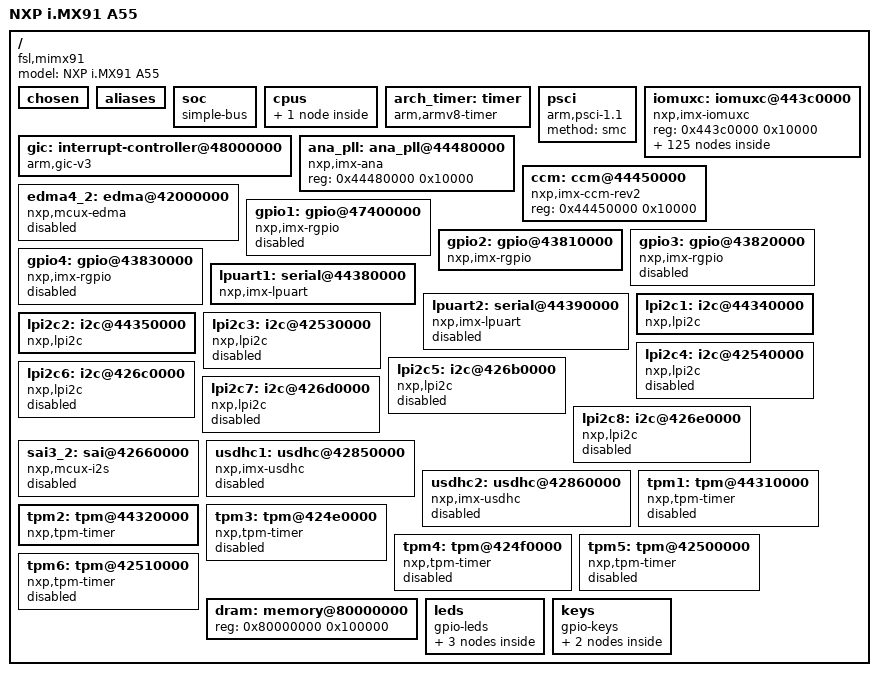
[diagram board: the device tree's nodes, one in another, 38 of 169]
/dts-v1/;

/* node '/' defined in zephyr/dts/common/skeleton.dtsi:9 */
/ {
	#address-cells = < 0x1 >;  /* in zephyr/dts/arm64/nxp/nxp_mimx9131.dtsi:16 */
	#size-cells = < 0x1 >;     /* in zephyr/dts/arm64/nxp/nxp_mimx9131.dtsi:17 */
	model = "NXP i.MX91 A55";  /* in zephyr/boards/nxp/imx91_evk/imx91_evk_mimx9131.dts:14 */
	compatible = "fsl,mimx91"; /* in zephyr/boards/nxp/imx91_evk/imx91_evk_mimx9131.dts:15 */

	/* node '/chosen' defined in zephyr/dts/common/skeleton.dtsi:13 */
	chosen {
		zephyr,console = &lpuart1;    /* in zephyr/boards/nxp/imx91_evk/imx91_evk_mimx9131.dts:18 */
		zephyr,shell-uart = &lpuart1; /* in zephyr/boards/nxp/imx91_evk/imx91_evk_mimx9131.dts:19 */
		zephyr,sram = &dram;          /* in zephyr/boards/nxp/imx91_evk/imx91_evk_mimx9131.dts:21 */
	};

	/* node '/aliases' defined in zephyr/dts/common/skeleton.dtsi:15 */
	aliases {
		led0 = &led_r; /* in zephyr/boards/nxp/imx91_evk/imx91_evk_mimx9131.dts:29 */
		led1 = &led_g; /* in zephyr/boards/nxp/imx91_evk/imx91_evk_mimx9131.dts:30 */
		sw0 = &btn_1;  /* in zephyr/boards/nxp/imx91_evk/imx91_evk_mimx9131.dts:31 */
	};

	/* node '/soc' defined in zephyr/dts/arm64/armv8-a.dtsi:10 */
	soc {
		#address-cells = < 0x1 >;  /* in zephyr/dts/arm64/armv8-a.dtsi:11 */
		#size-cells = < 0x1 >;     /* in zephyr/dts/arm64/armv8-a.dtsi:12 */
		compatible = "simple-bus"; /* in zephyr/dts/arm64/armv8-a.dtsi:13 */
		ranges;                    /* in zephyr/dts/arm64/armv8-a.dtsi:14 */
	};

	/* node '/cpus' defined in zephyr/dts/arm64/nxp/nxp_mimx9131.dtsi:19 */
	cpus {
		#address-cells = < 0x1 >; /* in zephyr/dts/arm64/nxp/nxp_mimx9131.dtsi:20 */
		#size-cells = < 0x0 >;    /* in zephyr/dts/arm64/nxp/nxp_mimx9131.dtsi:21 */

		/* node '/cpus/cpu@0' defined in zephyr/dts/arm64/nxp/nxp_mimx9131.dtsi:23 */
		cpu@0 {
			device_type = "cpu";           /* in zephyr/dts/arm64/nxp/nxp_mimx9131.dtsi:24 */
			compatible = "arm,cortex-a55"; /* in zephyr/dts/arm64/nxp/nxp_mimx9131.dtsi:25 */
			reg = < 0x0 >;                 /* in zephyr/dts/arm64/nxp/nxp_mimx9131.dtsi:26 */
		};
	};

	/* node '/timer' defined in zephyr/dts/arm64/nxp/nxp_mimx9131.dtsi:30 */
	arch_timer: timer {
		compatible = "arm,armv8-timer";    /* in zephyr/dts/arm64/nxp/nxp_mimx9131.dtsi:31 */
		interrupts = < 0x1 0xd 0x2 0xa0 >,
		             < 0x1 0xe 0x2 0xa0 >,
		             < 0x1 0xb 0x2 0xa0 >,
		             < 0x1 0xa 0x2 0xa0 >; /* in zephyr/dts/arm64/nxp/nxp_mimx9131.dtsi:32 */
		interrupt-parent = < &gic >;       /* in zephyr/dts/arm64/nxp/nxp_mimx9131.dtsi:40 */
	};

	/* node '/psci' defined in zephyr/dts/arm64/nxp/nxp_mimx9131.dtsi:43 */
	psci: psci {
		compatible = "arm,psci-1.1"; /* in zephyr/dts/arm64/nxp/nxp_mimx9131.dtsi:44 */
		method = "smc";              /* in zephyr/dts/arm64/nxp/nxp_mimx9131.dtsi:45 */
	};

	/* node '/interrupt-controller@48000000' defined in zephyr/dts/arm64/nxp/nxp_mimx9131.dtsi:48 */
	gic: interrupt-controller@48000000 {
		compatible = "arm,gic-v3",
		             "arm,gic";       /* in zephyr/dts/arm64/nxp/nxp_mimx9131.dtsi:49 */
		reg = < 0x48000000 0x10000 >,
		      < 0x48040000 0xc0000 >; /* in zephyr/dts/arm64/nxp/nxp_mimx9131.dtsi:50 */
		interrupt-controller;         /* in zephyr/dts/arm64/nxp/nxp_mimx9131.dtsi:52 */
		#interrupt-cells = < 0x4 >;   /* in zephyr/dts/arm64/nxp/nxp_mimx9131.dtsi:53 */
		status = "okay";              /* in zephyr/dts/arm64/nxp/nxp_mimx9131.dtsi:54 */
		phandle = < 0x1 >;            /* in zephyr/dts/arm64/nxp/nxp_mimx9131.dtsi:40 */
	};

	/* node '/iomuxc@443c0000' defined in zephyr/dts/arm64/nxp/nxp_mimx9131.dtsi:57 */
	iomuxc: iomuxc@443c0000 {
		compatible = "nxp,imx-iomuxc"; /* in zephyr/dts/arm64/nxp/nxp_mimx9131.dtsi:58 */
		reg = < 0x443c0000 0x10000 >;  /* in zephyr/dts/arm64/nxp/nxp_mimx9131.dtsi:59 */
		status = "okay";               /* in zephyr/dts/arm64/nxp/nxp_mimx9131.dtsi:60 */

		/* node '/iomuxc@443c0000/pinctrl' defined in zephyr/dts/arm64/nxp/nxp_mimx9131.dtsi:62 */
		pinctrl: pinctrl {
			status = "okay";                  /* in zephyr/dts/arm64/nxp/nxp_mimx9131.dtsi:63 */
			compatible = "nxp,imx93-pinctrl"; /* in zephyr/dts/arm64/nxp/nxp_mimx9131.dtsi:64 */

			/* node '/iomuxc@443c0000/pinctrl/uart1_default' defined in zephyr/boards/nxp/imx91_evk/imx91_evk-pinctrl.dtsi:10 */
			uart1_default: uart1_default {
				phandle = < 0x77 >; /* in zephyr/boards/nxp/imx91_evk/imx91_evk_mimx9131.dts:73 */

				/* node '/iomuxc@443c0000/pinctrl/uart1_default/group0' defined in zephyr/boards/nxp/imx91_evk/imx91_evk-pinctrl.dtsi:11 */
				group0 {
					pinmux = < &iomuxc1_uart1_rxd_lpuart_rx_lpuart1_rx >,
					         < &iomuxc1_uart1_txd_lpuart_tx_lpuart1_tx >; /* in zephyr/boards/nxp/imx91_evk/imx91_evk-pinctrl.dtsi:12 */
					bias-pull-up;                                         /* in zephyr/boards/nxp/imx91_evk/imx91_evk-pinctrl.dtsi:14 */
					slew-rate = "slightly_fast";                          /* in zephyr/boards/nxp/imx91_evk/imx91_evk-pinctrl.dtsi:15 */
					drive-strength = "x5";                                /* in zephyr/boards/nxp/imx91_evk/imx91_evk-pinctrl.dtsi:16 */
				};
			};

			/* node '/iomuxc@443c0000/pinctrl/uart2_default' defined in zephyr/boards/nxp/imx91_evk/imx91_evk-pinctrl.dtsi:20 */
			uart2_default: uart2_default {

				/* node '/iomuxc@443c0000/pinctrl/uart2_default/group0' defined in zephyr/boards/nxp/imx91_evk/imx91_evk-pinctrl.dtsi:21 */
				group0 {
					pinmux = < &iomuxc1_uart2_rxd_lpuart_rx_lpuart2_rx >,
					         < &iomuxc1_uart2_txd_lpuart_tx_lpuart2_tx >; /* in zephyr/boards/nxp/imx91_evk/imx91_evk-pinctrl.dtsi:22 */
					bias-pull-up;                                         /* in zephyr/boards/nxp/imx91_evk/imx91_evk-pinctrl.dtsi:24 */
					slew-rate = "slightly_fast";                          /* in zephyr/boards/nxp/imx91_evk/imx91_evk-pinctrl.dtsi:25 */
					drive-strength = "x5";                                /* in zephyr/boards/nxp/imx91_evk/imx91_evk-pinctrl.dtsi:26 */
				};
			};

			/* node '/iomuxc@443c0000/pinctrl/i2c1_default' defined in zephyr/boards/nxp/imx91_evk/imx91_evk-pinctrl.dtsi:30 */
			i2c1_default: i2c1_default {
				phandle = < 0x78 >; /* in zephyr/boards/nxp/imx91_evk/imx91_evk_mimx9131.dts:83 */

				/* node '/iomuxc@443c0000/pinctrl/i2c1_default/group0' defined in zephyr/boards/nxp/imx91_evk/imx91_evk-pinctrl.dtsi:31 */
				group0 {
					pinmux = < &iomuxc1_i2c1_scl_lpi2c_scl_lpi2c1_scl >,
					         < &iomuxc1_i2c1_sda_lpi2c_sda_lpi2c1_sda >; /* in zephyr/boards/nxp/imx91_evk/imx91_evk-pinctrl.dtsi:32 */
					drive-strength = "x5";                               /* in zephyr/boards/nxp/imx91_evk/imx91_evk-pinctrl.dtsi:34 */
					drive-open-drain;                                    /* in zephyr/boards/nxp/imx91_evk/imx91_evk-pinctrl.dtsi:35 */
					slew-rate = "fast";                                  /* in zephyr/boards/nxp/imx91_evk/imx91_evk-pinctrl.dtsi:36 */
					input-enable;                                        /* in zephyr/boards/nxp/imx91_evk/imx91_evk-pinctrl.dtsi:37 */
				};
			};

			/* node '/iomuxc@443c0000/pinctrl/i2c2_default' defined in zephyr/boards/nxp/imx91_evk/imx91_evk-pinctrl.dtsi:41 */
			i2c2_default: i2c2_default {
				phandle = < 0x79 >; /* in zephyr/boards/nxp/imx91_evk/imx91_evk_mimx9131.dts:90 */

				/* node '/iomuxc@443c0000/pinctrl/i2c2_default/group0' defined in zephyr/boards/nxp/imx91_evk/imx91_evk-pinctrl.dtsi:42 */
				group0 {
					pinmux = < &iomuxc1_i2c2_scl_lpi2c_scl_lpi2c2_scl >,
					         < &iomuxc1_i2c2_sda_lpi2c_sda_lpi2c2_sda >; /* in zephyr/boards/nxp/imx91_evk/imx91_evk-pinctrl.dtsi:43 */
					drive-strength = "x5";                               /* in zephyr/boards/nxp/imx91_evk/imx91_evk-pinctrl.dtsi:45 */
					drive-open-drain;                                    /* in zephyr/boards/nxp/imx91_evk/imx91_evk-pinctrl.dtsi:46 */
					slew-rate = "fast";                                  /* in zephyr/boards/nxp/imx91_evk/imx91_evk-pinctrl.dtsi:47 */
					input-enable;                                        /* in zephyr/boards/nxp/imx91_evk/imx91_evk-pinctrl.dtsi:48 */
				};
			};
		};

		/* node '/iomuxc@443c0000/IOMUXC1_CCM_CLKO1_GPIO_IO_GPIO3_IO26' defined in modules/hal/nxp/dts/nxp/nxp_imx/mimx9131cvvxj-pinctrl.dtsi:27 */
		iomuxc1_ccm_clko1_gpio_io_gpio3_io26: IOMUXC1_CCM_CLKO1_GPIO_IO_GPIO3_IO26 {
			pinmux = < 0x443c0088 0x5 0x0 0x0 0x443c0238 >; /* in modules/hal/nxp/dts/nxp/nxp_imx/mimx9131cvvxj-pinctrl.dtsi:28 */
			phandle = < 0x52 >;                             /* in zephyr/dts/arm64/nxp/nxp_mimx9131.dtsi:423 */
		};

		/* node '/iomuxc@443c0000/IOMUXC1_CCM_CLKO2_GPIO_IO_GPIO3_IO27' defined in modules/hal/nxp/dts/nxp/nxp_imx/mimx9131cvvxj-pinctrl.dtsi:36 */
		iomuxc1_ccm_clko2_gpio_io_gpio3_io27: IOMUXC1_CCM_CLKO2_GPIO_IO_GPIO3_IO27 {
			pinmux = < 0x443c008c 0x5 0x0 0x0 0x443c023c >; /* in modules/hal/nxp/dts/nxp/nxp_imx/mimx9131cvvxj-pinctrl.dtsi:37 */
			phandle = < 0x53 >;                             /* in zephyr/dts/arm64/nxp/nxp_mimx9131.dtsi:423 */
		};

		/* node '/iomuxc@443c0000/IOMUXC1_CCM_CLKO3_GPIO_IO_GPIO4_IO28' defined in modules/hal/nxp/dts/nxp/nxp_imx/mimx9131cvvxj-pinctrl.dtsi:45 */
		iomuxc1_ccm_clko3_gpio_io_gpio4_io28: IOMUXC1_CCM_CLKO3_GPIO_IO_GPIO4_IO28 {
			pinmux = < 0x443c0090 0x5 0x0 0x0 0x443c0240 >; /* in modules/hal/nxp/dts/nxp/nxp_imx/mimx9131cvvxj-pinctrl.dtsi:46 */
			phandle = < 0x74 >;                             /* in zephyr/dts/arm64/nxp/nxp_mimx9131.dtsi:458 */
		};

		/* node '/iomuxc@443c0000/IOMUXC1_CCM_CLKO4_GPIO_IO_GPIO4_IO29' defined in modules/hal/nxp/dts/nxp/nxp_imx/mimx9131cvvxj-pinctrl.dtsi:54 */
		iomuxc1_ccm_clko4_gpio_io_gpio4_io29: IOMUXC1_CCM_CLKO4_GPIO_IO_GPIO4_IO29 {
			pinmux = < 0x443c0094 0x5 0x0 0x0 0x443c0244 >; /* in modules/hal/nxp/dts/nxp/nxp_imx/mimx9131cvvxj-pinctrl.dtsi:55 */
			phandle = < 0x75 >;                             /* in zephyr/dts/arm64/nxp/nxp_mimx9131.dtsi:458 */
		};

		/* node '/iomuxc@443c0000/IOMUXC1_DAP_TCLK_SWCLK_GPIO_IO_GPIO3_IO30' defined in modules/hal/nxp/dts/nxp/nxp_imx/mimx9131cvvxj-pinctrl.dtsi:60 */
		iomuxc1_dap_tclk_swclk_gpio_io_gpio3_io30: IOMUXC1_DAP_TCLK_SWCLK_GPIO_IO_GPIO3_IO30 {
			pinmux = < 0x443c0008 0x5 0x0 0x0 0x443c01b8 >; /* in modules/hal/nxp/dts/nxp/nxp_imx/mimx9131cvvxj-pinctrl.dtsi:61 */
			phandle = < 0x56 >;                             /* in zephyr/dts/arm64/nxp/nxp_mimx9131.dtsi:423 */
		};

		/* node '/iomuxc@443c0000/IOMUXC1_DAP_TDI_GPIO_IO_GPIO3_IO28' defined in modules/hal/nxp/dts/nxp/nxp_imx/mimx9131cvvxj-pinctrl.dtsi:75 */
		iomuxc1_dap_tdi_gpio_io_gpio3_io28: IOMUXC1_DAP_TDI_GPIO_IO_GPIO3_IO28 {
			pinmux = < 0x443c0000 0x5 0x0 0x0 0x443c01b0 >; /* in modules/hal/nxp/dts/nxp/nxp_imx/mimx9131cvvxj-pinctrl.dtsi:76 */
			phandle = < 0x54 >;                             /* in zephyr/dts/arm64/nxp/nxp_mimx9131.dtsi:423 */
		};

		/* node '/iomuxc@443c0000/IOMUXC1_DAP_TDO_TRACESWO_GPIO_IO_GPIO3_IO31' defined in modules/hal/nxp/dts/nxp/nxp_imx/mimx9131cvvxj-pinctrl.dtsi:93 */
		iomuxc1_dap_tdo_traceswo_gpio_io_gpio3_io31: IOMUXC1_DAP_TDO_TRACESWO_GPIO_IO_GPIO3_IO31 {
			pinmux = < 0x443c000c 0x5 0x0 0x0 0x443c01bc >; /* in modules/hal/nxp/dts/nxp/nxp_imx/mimx9131cvvxj-pinctrl.dtsi:94 */
			phandle = < 0x57 >;                             /* in zephyr/dts/arm64/nxp/nxp_mimx9131.dtsi:423 */
		};

		/* node '/iomuxc@443c0000/IOMUXC1_DAP_TMS_SWDIO_GPIO_IO_GPIO3_IO29' defined in modules/hal/nxp/dts/nxp/nxp_imx/mimx9131cvvxj-pinctrl.dtsi:108 */
		iomuxc1_dap_tms_swdio_gpio_io_gpio3_io29: IOMUXC1_DAP_TMS_SWDIO_GPIO_IO_GPIO3_IO29 {
			pinmux = < 0x443c0004 0x5 0x0 0x0 0x443c01b4 >; /* in modules/hal/nxp/dts/nxp/nxp_imx/mimx9131cvvxj-pinctrl.dtsi:109 */
			phandle = < 0x55 >;                             /* in zephyr/dts/arm64/nxp/nxp_mimx9131.dtsi:423 */
		};

		/* node '/iomuxc@443c0000/IOMUXC1_ENET1_MDC_GPIO_IO_GPIO4_IO0' defined in modules/hal/nxp/dts/nxp/nxp_imx/mimx9131cvvxj-pinctrl.dtsi:123 */
		iomuxc1_enet1_mdc_gpio_io_gpio4_io0: IOMUXC1_ENET1_MDC_GPIO_IO_GPIO4_IO0 {
			pinmux = < 0x443c0098 0x5 0x0 0x0 0x443c0248 >; /* in modules/hal/nxp/dts/nxp/nxp_imx/mimx9131cvvxj-pinctrl.dtsi:124 */
			phandle = < 0x58 >;                             /* in zephyr/dts/arm64/nxp/nxp_mimx9131.dtsi:458 */
		};

		/* node '/iomuxc@443c0000/IOMUXC1_ENET1_MDIO_GPIO_IO_GPIO4_IO1' defined in modules/hal/nxp/dts/nxp/nxp_imx/mimx9131cvvxj-pinctrl.dtsi:144 */
		iomuxc1_enet1_mdio_gpio_io_gpio4_io1: IOMUXC1_ENET1_MDIO_GPIO_IO_GPIO4_IO1 {
			pinmux = < 0x443c009c 0x5 0x0 0x0 0x443c024c >; /* in modules/hal/nxp/dts/nxp/nxp_imx/mimx9131cvvxj-pinctrl.dtsi:145 */
			phandle = < 0x59 >;                             /* in zephyr/dts/arm64/nxp/nxp_mimx9131.dtsi:458 */
		};

		/* node '/iomuxc@443c0000/IOMUXC1_ENET1_RD0_GPIO_IO_GPIO4_IO10' defined in modules/hal/nxp/dts/nxp/nxp_imx/mimx9131cvvxj-pinctrl.dtsi:165 */
		iomuxc1_enet1_rd0_gpio_io_gpio4_io10: IOMUXC1_ENET1_RD0_GPIO_IO_GPIO4_IO10 {
			pinmux = < 0x443c00c0 0x5 0x0 0x0 0x443c0270 >; /* in modules/hal/nxp/dts/nxp/nxp_imx/mimx9131cvvxj-pinctrl.dtsi:166 */
			phandle = < 0x62 >;                             /* in zephyr/dts/arm64/nxp/nxp_mimx9131.dtsi:458 */
		};

		/* node '/iomuxc@443c0000/IOMUXC1_ENET1_RD1_GPIO_IO_GPIO4_IO11' defined in modules/hal/nxp/dts/nxp/nxp_imx/mimx9131cvvxj-pinctrl.dtsi:177 */
		iomuxc1_enet1_rd1_gpio_io_gpio4_io11: IOMUXC1_ENET1_RD1_GPIO_IO_GPIO4_IO11 {
			pinmux = < 0x443c00c4 0x5 0x0 0x0 0x443c0274 >; /* in modules/hal/nxp/dts/nxp/nxp_imx/mimx9131cvvxj-pinctrl.dtsi:178 */
			phandle = < 0x63 >;                             /* in zephyr/dts/arm64/nxp/nxp_mimx9131.dtsi:458 */
		};

		/* node '/iomuxc@443c0000/IOMUXC1_ENET1_RD2_GPIO_IO_GPIO4_IO12' defined in modules/hal/nxp/dts/nxp/nxp_imx/mimx9131cvvxj-pinctrl.dtsi:192 */
		iomuxc1_enet1_rd2_gpio_io_gpio4_io12: IOMUXC1_ENET1_RD2_GPIO_IO_GPIO4_IO12 {
			pinmux = < 0x443c00c8 0x5 0x0 0x0 0x443c0278 >; /* in modules/hal/nxp/dts/nxp/nxp_imx/mimx9131cvvxj-pinctrl.dtsi:193 */
			phandle = < 0x64 >;                             /* in zephyr/dts/arm64/nxp/nxp_mimx9131.dtsi:458 */
		};

		/* node '/iomuxc@443c0000/IOMUXC1_ENET1_RD3_GPIO_IO_GPIO4_IO13' defined in modules/hal/nxp/dts/nxp/nxp_imx/mimx9131cvvxj-pinctrl.dtsi:204 */
		iomuxc1_enet1_rd3_gpio_io_gpio4_io13: IOMUXC1_ENET1_RD3_GPIO_IO_GPIO4_IO13 {
			pinmux = < 0x443c00cc 0x5 0x0 0x0 0x443c027c >; /* in modules/hal/nxp/dts/nxp/nxp_imx/mimx9131cvvxj-pinctrl.dtsi:205 */
			phandle = < 0x65 >;                             /* in zephyr/dts/arm64/nxp/nxp_mimx9131.dtsi:458 */
		};

		/* node '/iomuxc@443c0000/IOMUXC1_ENET1_RXC_GPIO_IO_GPIO4_IO9' defined in modules/hal/nxp/dts/nxp/nxp_imx/mimx9131cvvxj-pinctrl.dtsi:219 */
		iomuxc1_enet1_rxc_gpio_io_gpio4_io9: IOMUXC1_ENET1_RXC_GPIO_IO_GPIO4_IO9 {
			pinmux = < 0x443c00bc 0x5 0x0 0x0 0x443c026c >; /* in modules/hal/nxp/dts/nxp/nxp_imx/mimx9131cvvxj-pinctrl.dtsi:220 */
			phandle = < 0x61 >;                             /* in zephyr/dts/arm64/nxp/nxp_mimx9131.dtsi:458 */
		};

		/* node '/iomuxc@443c0000/IOMUXC1_ENET1_RX_CTL_GPIO_IO_GPIO4_IO8' defined in modules/hal/nxp/dts/nxp/nxp_imx/mimx9131cvvxj-pinctrl.dtsi:231 */
		iomuxc1_enet1_rx_ctl_gpio_io_gpio4_io8: IOMUXC1_ENET1_RX_CTL_GPIO_IO_GPIO4_IO8 {
			pinmux = < 0x443c00b8 0x5 0x0 0x0 0x443c0268 >; /* in modules/hal/nxp/dts/nxp/nxp_imx/mimx9131cvvxj-pinctrl.dtsi:232 */
			phandle = < 0x60 >;                             /* in zephyr/dts/arm64/nxp/nxp_mimx9131.dtsi:458 */
		};

		/* node '/iomuxc@443c0000/IOMUXC1_ENET1_TD0_GPIO_IO_GPIO4_IO5' defined in modules/hal/nxp/dts/nxp/nxp_imx/mimx9131cvvxj-pinctrl.dtsi:249 */
		iomuxc1_enet1_td0_gpio_io_gpio4_io5: IOMUXC1_ENET1_TD0_GPIO_IO_GPIO4_IO5 {
			pinmux = < 0x443c00ac 0x5 0x0 0x0 0x443c025c >; /* in modules/hal/nxp/dts/nxp/nxp_imx/mimx9131cvvxj-pinctrl.dtsi:250 */
			phandle = < 0x5d >;                             /* in zephyr/dts/arm64/nxp/nxp_mimx9131.dtsi:458 */
		};

		/* node '/iomuxc@443c0000/IOMUXC1_ENET1_TD1_GPIO_IO_GPIO4_IO4' defined in modules/hal/nxp/dts/nxp/nxp_imx/mimx9131cvvxj-pinctrl.dtsi:261 */
		iomuxc1_enet1_td1_gpio_io_gpio4_io4: IOMUXC1_ENET1_TD1_GPIO_IO_GPIO4_IO4 {
			pinmux = < 0x443c00a8 0x5 0x0 0x0 0x443c0258 >; /* in modules/hal/nxp/dts/nxp/nxp_imx/mimx9131cvvxj-pinctrl.dtsi:262 */
			phandle = < 0x5c >;                             /* in zephyr/dts/arm64/nxp/nxp_mimx9131.dtsi:458 */
		};

		/* node '/iomuxc@443c0000/IOMUXC1_ENET1_TD2_GPIO_IO_GPIO4_IO3' defined in modules/hal/nxp/dts/nxp/nxp_imx/mimx9131cvvxj-pinctrl.dtsi:288 */
		iomuxc1_enet1_td2_gpio_io_gpio4_io3: IOMUXC1_ENET1_TD2_GPIO_IO_GPIO4_IO3 {
			pinmux = < 0x443c00a4 0x5 0x0 0x0 0x443c0254 >; /* in modules/hal/nxp/dts/nxp/nxp_imx/mimx9131cvvxj-pinctrl.dtsi:289 */
			phandle = < 0x5b >;                             /* in zephyr/dts/arm64/nxp/nxp_mimx9131.dtsi:458 */
		};

		/* node '/iomuxc@443c0000/IOMUXC1_ENET1_TD3_GPIO_IO_GPIO4_IO2' defined in modules/hal/nxp/dts/nxp/nxp_imx/mimx9131cvvxj-pinctrl.dtsi:306 */
		iomuxc1_enet1_td3_gpio_io_gpio4_io2: IOMUXC1_ENET1_TD3_GPIO_IO_GPIO4_IO2 {
			pinmux = < 0x443c00a0 0x5 0x0 0x0 0x443c0250 >; /* in modules/hal/nxp/dts/nxp/nxp_imx/mimx9131cvvxj-pinctrl.dtsi:307 */
			phandle = < 0x5a >;                             /* in zephyr/dts/arm64/nxp/nxp_mimx9131.dtsi:458 */
		};

		/* node '/iomuxc@443c0000/IOMUXC1_ENET1_TXC_GPIO_IO_GPIO4_IO7' defined in modules/hal/nxp/dts/nxp/nxp_imx/mimx9131cvvxj-pinctrl.dtsi:324 */
		iomuxc1_enet1_txc_gpio_io_gpio4_io7: IOMUXC1_ENET1_TXC_GPIO_IO_GPIO4_IO7 {
			pinmux = < 0x443c00b4 0x5 0x0 0x0 0x443c0264 >; /* in modules/hal/nxp/dts/nxp/nxp_imx/mimx9131cvvxj-pinctrl.dtsi:325 */
			phandle = < 0x5f >;                             /* in zephyr/dts/arm64/nxp/nxp_mimx9131.dtsi:458 */
		};

		/* node '/iomuxc@443c0000/IOMUXC1_ENET1_TX_CTL_GPIO_IO_GPIO4_IO6' defined in modules/hal/nxp/dts/nxp/nxp_imx/mimx9131cvvxj-pinctrl.dtsi:336 */
		iomuxc1_enet1_tx_ctl_gpio_io_gpio4_io6: IOMUXC1_ENET1_TX_CTL_GPIO_IO_GPIO4_IO6 {
			pinmux = < 0x443c00b0 0x5 0x0 0x0 0x443c0260 >; /* in modules/hal/nxp/dts/nxp/nxp_imx/mimx9131cvvxj-pinctrl.dtsi:337 */
			phandle = < 0x5e >;                             /* in zephyr/dts/arm64/nxp/nxp_mimx9131.dtsi:458 */
		};

		/* node '/iomuxc@443c0000/IOMUXC1_ENET2_MDC_GPIO_IO_GPIO4_IO14' defined in modules/hal/nxp/dts/nxp/nxp_imx/mimx9131cvvxj-pinctrl.dtsi:351 */
		iomuxc1_enet2_mdc_gpio_io_gpio4_io14: IOMUXC1_ENET2_MDC_GPIO_IO_GPIO4_IO14 {
			pinmux = < 0x443c00d0 0x5 0x0 0x0 0x443c0280 >; /* in modules/hal/nxp/dts/nxp/nxp_imx/mimx9131cvvxj-pinctrl.dtsi:352 */
			phandle = < 0x66 >;                             /* in zephyr/dts/arm64/nxp/nxp_mimx9131.dtsi:458 */
		};

		/* node '/iomuxc@443c0000/IOMUXC1_ENET2_MDIO_GPIO_IO_GPIO4_IO15' defined in modules/hal/nxp/dts/nxp/nxp_imx/mimx9131cvvxj-pinctrl.dtsi:369 */
		iomuxc1_enet2_mdio_gpio_io_gpio4_io15: IOMUXC1_ENET2_MDIO_GPIO_IO_GPIO4_IO15 {
			pinmux = < 0x443c00d4 0x5 0x0 0x0 0x443c0284 >; /* in modules/hal/nxp/dts/nxp/nxp_imx/mimx9131cvvxj-pinctrl.dtsi:370 */
			phandle = < 0x67 >;                             /* in zephyr/dts/arm64/nxp/nxp_mimx9131.dtsi:458 */
		};

		/* node '/iomuxc@443c0000/IOMUXC1_ENET2_RD0_GPIO_IO_GPIO4_IO24' defined in modules/hal/nxp/dts/nxp/nxp_imx/mimx9131cvvxj-pinctrl.dtsi:387 */
		iomuxc1_enet2_rd0_gpio_io_gpio4_io24: IOMUXC1_ENET2_RD0_GPIO_IO_GPIO4_IO24 {
			pinmux = < 0x443c00f8 0x5 0x0 0x0 0x443c02a8 >; /* in modules/hal/nxp/dts/nxp/nxp_imx/mimx9131cvvxj-pinctrl.dtsi:388 */
			phandle = < 0x70 >;                             /* in zephyr/dts/arm64/nxp/nxp_mimx9131.dtsi:458 */
		};

		/* node '/iomuxc@443c0000/IOMUXC1_ENET2_RD1_GPIO_IO_GPIO4_IO25' defined in modules/hal/nxp/dts/nxp/nxp_imx/mimx9131cvvxj-pinctrl.dtsi:402 */
		iomuxc1_enet2_rd1_gpio_io_gpio4_io25: IOMUXC1_ENET2_RD1_GPIO_IO_GPIO4_IO25 {
			pinmux = < 0x443c00fc 0x5 0x0 0x0 0x443c02ac >; /* in modules/hal/nxp/dts/nxp/nxp_imx/mimx9131cvvxj-pinctrl.dtsi:403 */
			phandle = < 0x71 >;                             /* in zephyr/dts/arm64/nxp/nxp_mimx9131.dtsi:458 */
		};

		/* node '/iomuxc@443c0000/IOMUXC1_ENET2_RD2_GPIO_IO_GPIO4_IO26' defined in modules/hal/nxp/dts/nxp/nxp_imx/mimx9131cvvxj-pinctrl.dtsi:417 */
		iomuxc1_enet2_rd2_gpio_io_gpio4_io26: IOMUXC1_ENET2_RD2_GPIO_IO_GPIO4_IO26 {
			pinmux = < 0x443c0100 0x5 0x0 0x0 0x443c02b0 >; /* in modules/hal/nxp/dts/nxp/nxp_imx/mimx9131cvvxj-pinctrl.dtsi:418 */
			phandle = < 0x72 >;                             /* in zephyr/dts/arm64/nxp/nxp_mimx9131.dtsi:458 */
		};

		/* node '/iomuxc@443c0000/IOMUXC1_ENET2_RD3_GPIO_IO_GPIO4_IO27' defined in modules/hal/nxp/dts/nxp/nxp_imx/mimx9131cvvxj-pinctrl.dtsi:438 */
		iomuxc1_enet2_rd3_gpio_io_gpio4_io27: IOMUXC1_ENET2_RD3_GPIO_IO_GPIO4_IO27 {
			pinmux = < 0x443c0104 0x5 0x0 0x0 0x443c02b4 >; /* in modules/hal/nxp/dts/nxp/nxp_imx/mimx9131cvvxj-pinctrl.dtsi:439 */
			phandle = < 0x73 >;                             /* in zephyr/dts/arm64/nxp/nxp_mimx9131.dtsi:458 */
		};

		/* node '/iomuxc@443c0000/IOMUXC1_ENET2_RXC_GPIO_IO_GPIO4_IO23' defined in modules/hal/nxp/dts/nxp/nxp_imx/mimx9131cvvxj-pinctrl.dtsi:459 */
		iomuxc1_enet2_rxc_gpio_io_gpio4_io23: IOMUXC1_ENET2_RXC_GPIO_IO_GPIO4_IO23 {
			pinmux = < 0x443c00f4 0x5 0x0 0x0 0x443c02a4 >; /* in modules/hal/nxp/dts/nxp/nxp_imx/mimx9131cvvxj-pinctrl.dtsi:460 */
			phandle = < 0x6f >;                             /* in zephyr/dts/arm64/nxp/nxp_mimx9131.dtsi:458 */
		};

		/* node '/iomuxc@443c0000/IOMUXC1_ENET2_RX_CTL_GPIO_IO_GPIO4_IO22' defined in modules/hal/nxp/dts/nxp/nxp_imx/mimx9131cvvxj-pinctrl.dtsi:471 */
		iomuxc1_enet2_rx_ctl_gpio_io_gpio4_io22: IOMUXC1_ENET2_RX_CTL_GPIO_IO_GPIO4_IO22 {
			pinmux = < 0x443c00f0 0x5 0x0 0x0 0x443c02a0 >; /* in modules/hal/nxp/dts/nxp/nxp_imx/mimx9131cvvxj-pinctrl.dtsi:472 */
			phandle = < 0x6e >;                             /* in zephyr/dts/arm64/nxp/nxp_mimx9131.dtsi:458 */
		};

		/* node '/iomuxc@443c0000/IOMUXC1_ENET2_TD0_GPIO_IO_GPIO4_IO19' defined in modules/hal/nxp/dts/nxp/nxp_imx/mimx9131cvvxj-pinctrl.dtsi:489 */
		iomuxc1_enet2_td0_gpio_io_gpio4_io19: IOMUXC1_ENET2_TD0_GPIO_IO_GPIO4_IO19 {
			pinmux = < 0x443c00e4 0x5 0x0 0x0 0x443c0294 >; /* in modules/hal/nxp/dts/nxp/nxp_imx/mimx9131cvvxj-pinctrl.dtsi:490 */
			phandle = < 0x6b >;                             /* in zephyr/dts/arm64/nxp/nxp_mimx9131.dtsi:458 */
		};

		/* node '/iomuxc@443c0000/IOMUXC1_ENET2_TD1_GPIO_IO_GPIO4_IO18' defined in modules/hal/nxp/dts/nxp/nxp_imx/mimx9131cvvxj-pinctrl.dtsi:504 */
		iomuxc1_enet2_td1_gpio_io_gpio4_io18: IOMUXC1_ENET2_TD1_GPIO_IO_GPIO4_IO18 {
			pinmux = < 0x443c00e0 0x5 0x0 0x0 0x443c0290 >; /* in modules/hal/nxp/dts/nxp/nxp_imx/mimx9131cvvxj-pinctrl.dtsi:505 */
			phandle = < 0x6a >;                             /* in zephyr/dts/arm64/nxp/nxp_mimx9131.dtsi:458 */
		};

		/* node '/iomuxc@443c0000/IOMUXC1_ENET2_TD2_GPIO_IO_GPIO4_IO17' defined in modules/hal/nxp/dts/nxp/nxp_imx/mimx9131cvvxj-pinctrl.dtsi:522 */
		iomuxc1_enet2_td2_gpio_io_gpio4_io17: IOMUXC1_ENET2_TD2_GPIO_IO_GPIO4_IO17 {
			pinmux = < 0x443c00dc 0x5 0x0 0x0 0x443c028c >; /* in modules/hal/nxp/dts/nxp/nxp_imx/mimx9131cvvxj-pinctrl.dtsi:523 */
			phandle = < 0x69 >;                             /* in zephyr/dts/arm64/nxp/nxp_mimx9131.dtsi:458 */
		};

		/* node '/iomuxc@443c0000/IOMUXC1_ENET2_TD3_GPIO_IO_GPIO4_IO16' defined in modules/hal/nxp/dts/nxp/nxp_imx/mimx9131cvvxj-pinctrl.dtsi:534 */
		iomuxc1_enet2_td3_gpio_io_gpio4_io16: IOMUXC1_ENET2_TD3_GPIO_IO_GPIO4_IO16 {
			pinmux = < 0x443c00d8 0x5 0x0 0x0 0x443c0288 >; /* in modules/hal/nxp/dts/nxp/nxp_imx/mimx9131cvvxj-pinctrl.dtsi:535 */
			phandle = < 0x68 >;                             /* in zephyr/dts/arm64/nxp/nxp_mimx9131.dtsi:458 */
		};

		/* node '/iomuxc@443c0000/IOMUXC1_ENET2_TXC_GPIO_IO_GPIO4_IO21' defined in modules/hal/nxp/dts/nxp/nxp_imx/mimx9131cvvxj-pinctrl.dtsi:552 */
		iomuxc1_enet2_txc_gpio_io_gpio4_io21: IOMUXC1_ENET2_TXC_GPIO_IO_GPIO4_IO21 {
			pinmux = < 0x443c00ec 0x5 0x0 0x0 0x443c029c >; /* in modules/hal/nxp/dts/nxp/nxp_imx/mimx9131cvvxj-pinctrl.dtsi:553 */
			phandle = < 0x6d >;                             /* in zephyr/dts/arm64/nxp/nxp_mimx9131.dtsi:458 */
		};

		/* node '/iomuxc@443c0000/IOMUXC1_ENET2_TX_CTL_GPIO_IO_GPIO4_IO20' defined in modules/hal/nxp/dts/nxp/nxp_imx/mimx9131cvvxj-pinctrl.dtsi:567 */
		iomuxc1_enet2_tx_ctl_gpio_io_gpio4_io20: IOMUXC1_ENET2_TX_CTL_GPIO_IO_GPIO4_IO20 {
			pinmux = < 0x443c00e8 0x5 0x0 0x0 0x443c0298 >; /* in modules/hal/nxp/dts/nxp/nxp_imx/mimx9131cvvxj-pinctrl.dtsi:568 */
			phandle = < 0x6c >;                             /* in zephyr/dts/arm64/nxp/nxp_mimx9131.dtsi:458 */
		};

		/* node '/iomuxc@443c0000/IOMUXC1_GPIO_IO00_GPIO_IO_GPIO2_IO0' defined in modules/hal/nxp/dts/nxp/nxp_imx/mimx9131cvvxj-pinctrl.dtsi:582 */
		iomuxc1_gpio_io00_gpio_io_gpio2_io0: IOMUXC1_GPIO_IO00_GPIO_IO_GPIO2_IO0 {
			pinmux = < 0x443c0010 0x0 0x0 0x0 0x443c01c0 >; /* in modules/hal/nxp/dts/nxp/nxp_imx/mimx9131cvvxj-pinctrl.dtsi:583 */
			phandle = < 0x1a >;                             /* in zephyr/dts/arm64/nxp/nxp_mimx9131.dtsi:390 */
		};

		/* node '/iomuxc@443c0000/IOMUXC1_GPIO_IO01_GPIO_IO_GPIO2_IO1' defined in modules/hal/nxp/dts/nxp/nxp_imx/mimx9131cvvxj-pinctrl.dtsi:606 */
		iomuxc1_gpio_io01_gpio_io_gpio2_io1: IOMUXC1_GPIO_IO01_GPIO_IO_GPIO2_IO1 {
			pinmux = < 0x443c0014 0x0 0x0 0x0 0x443c01c4 >; /* in modules/hal/nxp/dts/nxp/nxp_imx/mimx9131cvvxj-pinctrl.dtsi:607 */
			phandle = < 0x1b >;                             /* in zephyr/dts/arm64/nxp/nxp_mimx9131.dtsi:390 */
		};

		/* node '/iomuxc@443c0000/IOMUXC1_GPIO_IO02_GPIO_IO_GPIO2_IO2' defined in modules/hal/nxp/dts/nxp/nxp_imx/mimx9131cvvxj-pinctrl.dtsi:630 */
		iomuxc1_gpio_io02_gpio_io_gpio2_io2: IOMUXC1_GPIO_IO02_GPIO_IO_GPIO2_IO2 {
			pinmux = < 0x443c0018 0x0 0x0 0x0 0x443c01c8 >; /* in modules/hal/nxp/dts/nxp/nxp_imx/mimx9131cvvxj-pinctrl.dtsi:631 */
			phandle = < 0x1c >;                             /* in zephyr/dts/arm64/nxp/nxp_mimx9131.dtsi:390 */
		};

		/* node '/iomuxc@443c0000/IOMUXC1_GPIO_IO03_GPIO_IO_GPIO2_IO3' defined in modules/hal/nxp/dts/nxp/nxp_imx/mimx9131cvvxj-pinctrl.dtsi:654 */
		iomuxc1_gpio_io03_gpio_io_gpio2_io3: IOMUXC1_GPIO_IO03_GPIO_IO_GPIO2_IO3 {
			pinmux = < 0x443c001c 0x0 0x0 0x0 0x443c01cc >; /* in modules/hal/nxp/dts/nxp/nxp_imx/mimx9131cvvxj-pinctrl.dtsi:655 */
			phandle = < 0x1d >;                             /* in zephyr/dts/arm64/nxp/nxp_mimx9131.dtsi:390 */
		};

		/* node '/iomuxc@443c0000/IOMUXC1_GPIO_IO04_GPIO_IO_GPIO2_IO4' defined in modules/hal/nxp/dts/nxp/nxp_imx/mimx9131cvvxj-pinctrl.dtsi:678 */
		iomuxc1_gpio_io04_gpio_io_gpio2_io4: IOMUXC1_GPIO_IO04_GPIO_IO_GPIO2_IO4 {
			pinmux = < 0x443c0020 0x0 0x0 0x0 0x443c01d0 >; /* in modules/hal/nxp/dts/nxp/nxp_imx/mimx9131cvvxj-pinctrl.dtsi:679 */
			phandle = < 0x1e >;                             /* in zephyr/dts/arm64/nxp/nxp_mimx9131.dtsi:390 */
		};

		/* node '/iomuxc@443c0000/IOMUXC1_GPIO_IO05_GPIO_IO_GPIO2_IO5' defined in modules/hal/nxp/dts/nxp/nxp_imx/mimx9131cvvxj-pinctrl.dtsi:702 */
		iomuxc1_gpio_io05_gpio_io_gpio2_io5: IOMUXC1_GPIO_IO05_GPIO_IO_GPIO2_IO5 {
			pinmux = < 0x443c0024 0x0 0x0 0x0 0x443c01d4 >; /* in modules/hal/nxp/dts/nxp/nxp_imx/mimx9131cvvxj-pinctrl.dtsi:703 */
			phandle = < 0x1f >;                             /* in zephyr/dts/arm64/nxp/nxp_mimx9131.dtsi:390 */
		};

		/* node '/iomuxc@443c0000/IOMUXC1_GPIO_IO06_GPIO_IO_GPIO2_IO6' defined in modules/hal/nxp/dts/nxp/nxp_imx/mimx9131cvvxj-pinctrl.dtsi:726 */
		iomuxc1_gpio_io06_gpio_io_gpio2_io6: IOMUXC1_GPIO_IO06_GPIO_IO_GPIO2_IO6 {
			pinmux = < 0x443c0028 0x0 0x0 0x0 0x443c01d8 >; /* in modules/hal/nxp/dts/nxp/nxp_imx/mimx9131cvvxj-pinctrl.dtsi:727 */
			phandle = < 0x20 >;                             /* in zephyr/dts/arm64/nxp/nxp_mimx9131.dtsi:390 */
		};

		/* node '/iomuxc@443c0000/IOMUXC1_GPIO_IO07_GPIO_IO_GPIO2_IO7' defined in modules/hal/nxp/dts/nxp/nxp_imx/mimx9131cvvxj-pinctrl.dtsi:750 */
		iomuxc1_gpio_io07_gpio_io_gpio2_io7: IOMUXC1_GPIO_IO07_GPIO_IO_GPIO2_IO7 {
			pinmux = < 0x443c002c 0x0 0x0 0x0 0x443c01dc >; /* in modules/hal/nxp/dts/nxp/nxp_imx/mimx9131cvvxj-pinctrl.dtsi:751 */
			phandle = < 0x21 >;                             /* in zephyr/dts/arm64/nxp/nxp_mimx9131.dtsi:390 */
		};

		/* node '/iomuxc@443c0000/IOMUXC1_GPIO_IO08_GPIO_IO_GPIO2_IO8' defined in modules/hal/nxp/dts/nxp/nxp_imx/mimx9131cvvxj-pinctrl.dtsi:774 */
		iomuxc1_gpio_io08_gpio_io_gpio2_io8: IOMUXC1_GPIO_IO08_GPIO_IO_GPIO2_IO8 {
			pinmux = < 0x443c0030 0x0 0x0 0x0 0x443c01e0 >; /* in modules/hal/nxp/dts/nxp/nxp_imx/mimx9131cvvxj-pinctrl.dtsi:775 */
			phandle = < 0x22 >;                             /* in zephyr/dts/arm64/nxp/nxp_mimx9131.dtsi:390 */
		};

		/* node '/iomuxc@443c0000/IOMUXC1_GPIO_IO09_GPIO_IO_GPIO2_IO9' defined in modules/hal/nxp/dts/nxp/nxp_imx/mimx9131cvvxj-pinctrl.dtsi:798 */
		iomuxc1_gpio_io09_gpio_io_gpio2_io9: IOMUXC1_GPIO_IO09_GPIO_IO_GPIO2_IO9 {
			pinmux = < 0x443c0034 0x0 0x0 0x0 0x443c01e4 >; /* in modules/hal/nxp/dts/nxp/nxp_imx/mimx9131cvvxj-pinctrl.dtsi:799 */
			phandle = < 0x23 >;                             /* in zephyr/dts/arm64/nxp/nxp_mimx9131.dtsi:390 */
		};

		/* node '/iomuxc@443c0000/IOMUXC1_GPIO_IO10_GPIO_IO_GPIO2_IO10' defined in modules/hal/nxp/dts/nxp/nxp_imx/mimx9131cvvxj-pinctrl.dtsi:822 */
		iomuxc1_gpio_io10_gpio_io_gpio2_io10: IOMUXC1_GPIO_IO10_GPIO_IO_GPIO2_IO10 {
			pinmux = < 0x443c0038 0x0 0x0 0x0 0x443c01e8 >; /* in modules/hal/nxp/dts/nxp/nxp_imx/mimx9131cvvxj-pinctrl.dtsi:823 */
			phandle = < 0x24 >;                             /* in zephyr/dts/arm64/nxp/nxp_mimx9131.dtsi:390 */
		};

		/* node '/iomuxc@443c0000/IOMUXC1_GPIO_IO11_GPIO_IO_GPIO2_IO11' defined in modules/hal/nxp/dts/nxp/nxp_imx/mimx9131cvvxj-pinctrl.dtsi:846 */
		iomuxc1_gpio_io11_gpio_io_gpio2_io11: IOMUXC1_GPIO_IO11_GPIO_IO_GPIO2_IO11 {
			pinmux = < 0x443c003c 0x0 0x0 0x0 0x443c01ec >; /* in modules/hal/nxp/dts/nxp/nxp_imx/mimx9131cvvxj-pinctrl.dtsi:847 */
			phandle = < 0x25 >;                             /* in zephyr/dts/arm64/nxp/nxp_mimx9131.dtsi:390 */
		};

		/* node '/iomuxc@443c0000/IOMUXC1_GPIO_IO12_GPIO_IO_GPIO2_IO12' defined in modules/hal/nxp/dts/nxp/nxp_imx/mimx9131cvvxj-pinctrl.dtsi:867 */
		iomuxc1_gpio_io12_gpio_io_gpio2_io12: IOMUXC1_GPIO_IO12_GPIO_IO_GPIO2_IO12 {
			pinmux = < 0x443c0040 0x0 0x0 0x0 0x443c01f0 >; /* in modules/hal/nxp/dts/nxp/nxp_imx/mimx9131cvvxj-pinctrl.dtsi:868 */
			phandle = < 0x26 >;                             /* in zephyr/dts/arm64/nxp/nxp_mimx9131.dtsi:390 */
		};

		/* node '/iomuxc@443c0000/IOMUXC1_GPIO_IO13_GPIO_IO_GPIO2_IO13' defined in modules/hal/nxp/dts/nxp/nxp_imx/mimx9131cvvxj-pinctrl.dtsi:894 */
		iomuxc1_gpio_io13_gpio_io_gpio2_io13: IOMUXC1_GPIO_IO13_GPIO_IO_GPIO2_IO13 {
			pinmux = < 0x443c0044 0x0 0x0 0x0 0x443c01f4 >; /* in modules/hal/nxp/dts/nxp/nxp_imx/mimx9131cvvxj-pinctrl.dtsi:895 */
			phandle = < 0x27 >;                             /* in zephyr/dts/arm64/nxp/nxp_mimx9131.dtsi:390 */
		};

		/* node '/iomuxc@443c0000/IOMUXC1_GPIO_IO14_GPIO_IO_GPIO2_IO14' defined in modules/hal/nxp/dts/nxp/nxp_imx/mimx9131cvvxj-pinctrl.dtsi:918 */
		iomuxc1_gpio_io14_gpio_io_gpio2_io14: IOMUXC1_GPIO_IO14_GPIO_IO_GPIO2_IO14 {
			pinmux = < 0x443c0048 0x0 0x0 0x0 0x443c01f8 >; /* in modules/hal/nxp/dts/nxp/nxp_imx/mimx9131cvvxj-pinctrl.dtsi:919 */
			phandle = < 0x28 >;                             /* in zephyr/dts/arm64/nxp/nxp_mimx9131.dtsi:390 */
		};

		/* node '/iomuxc@443c0000/IOMUXC1_GPIO_IO15_GPIO_IO_GPIO2_IO15' defined in modules/hal/nxp/dts/nxp/nxp_imx/mimx9131cvvxj-pinctrl.dtsi:942 */
		iomuxc1_gpio_io15_gpio_io_gpio2_io15: IOMUXC1_GPIO_IO15_GPIO_IO_GPIO2_IO15 {
			pinmux = < 0x443c004c 0x0 0x0 0x0 0x443c01fc >; /* in modules/hal/nxp/dts/nxp/nxp_imx/mimx9131cvvxj-pinctrl.dtsi:943 */
			phandle = < 0x29 >;                             /* in zephyr/dts/arm64/nxp/nxp_mimx9131.dtsi:390 */
		};

		/* node '/iomuxc@443c0000/IOMUXC1_GPIO_IO16_GPIO_IO_GPIO2_IO16' defined in modules/hal/nxp/dts/nxp/nxp_imx/mimx9131cvvxj-pinctrl.dtsi:966 */
		iomuxc1_gpio_io16_gpio_io_gpio2_io16: IOMUXC1_GPIO_IO16_GPIO_IO_GPIO2_IO16 {
			pinmux = < 0x443c0050 0x0 0x0 0x0 0x443c0200 >; /* in modules/hal/nxp/dts/nxp/nxp_imx/mimx9131cvvxj-pinctrl.dtsi:967 */
			phandle = < 0x2a >;                             /* in zephyr/dts/arm64/nxp/nxp_mimx9131.dtsi:390 */
		};

		/* node '/iomuxc@443c0000/IOMUXC1_GPIO_IO17_GPIO_IO_GPIO2_IO17' defined in modules/hal/nxp/dts/nxp/nxp_imx/mimx9131cvvxj-pinctrl.dtsi:990 */
		iomuxc1_gpio_io17_gpio_io_gpio2_io17: IOMUXC1_GPIO_IO17_GPIO_IO_GPIO2_IO17 {
			pinmux = < 0x443c0054 0x0 0x0 0x0 0x443c0204 >; /* in modules/hal/nxp/dts/nxp/nxp_imx/mimx9131cvvxj-pinctrl.dtsi:991 */
			phandle = < 0x2b >;                             /* in zephyr/dts/arm64/nxp/nxp_mimx9131.dtsi:390 */
		};

		/* node '/iomuxc@443c0000/IOMUXC1_GPIO_IO18_GPIO_IO_GPIO2_IO18' defined in modules/hal/nxp/dts/nxp/nxp_imx/mimx9131cvvxj-pinctrl.dtsi:1014 */
		iomuxc1_gpio_io18_gpio_io_gpio2_io18: IOMUXC1_GPIO_IO18_GPIO_IO_GPIO2_IO18 {
			pinmux = < 0x443c0058 0x0 0x0 0x0 0x443c0208 >; /* in modules/hal/nxp/dts/nxp/nxp_imx/mimx9131cvvxj-pinctrl.dtsi:1015 */
			phandle = < 0x2c >;                             /* in zephyr/dts/arm64/nxp/nxp_mimx9131.dtsi:390 */
		};

		/* node '/iomuxc@443c0000/IOMUXC1_GPIO_IO19_GPIO_IO_GPIO2_IO19' defined in modules/hal/nxp/dts/nxp/nxp_imx/mimx9131cvvxj-pinctrl.dtsi:1035 */
		iomuxc1_gpio_io19_gpio_io_gpio2_io19: IOMUXC1_GPIO_IO19_GPIO_IO_GPIO2_IO19 {
			pinmux = < 0x443c005c 0x0 0x0 0x0 0x443c020c >; /* in modules/hal/nxp/dts/nxp/nxp_imx/mimx9131cvvxj-pinctrl.dtsi:1036 */
			phandle = < 0x2d >;                             /* in zephyr/dts/arm64/nxp/nxp_mimx9131.dtsi:390 */
		};

		/* node '/iomuxc@443c0000/IOMUXC1_GPIO_IO20_GPIO_IO_GPIO2_IO20' defined in modules/hal/nxp/dts/nxp/nxp_imx/mimx9131cvvxj-pinctrl.dtsi:1062 */
		iomuxc1_gpio_io20_gpio_io_gpio2_io20: IOMUXC1_GPIO_IO20_GPIO_IO_GPIO2_IO20 {
			pinmux = < 0x443c0060 0x0 0x0 0x0 0x443c0210 >; /* in modules/hal/nxp/dts/nxp/nxp_imx/mimx9131cvvxj-pinctrl.dtsi:1063 */
			phandle = < 0x2e >;                             /* in zephyr/dts/arm64/nxp/nxp_mimx9131.dtsi:390 */
		};

		/* node '/iomuxc@443c0000/IOMUXC1_GPIO_IO21_GPIO_IO_GPIO2_IO21' defined in modules/hal/nxp/dts/nxp/nxp_imx/mimx9131cvvxj-pinctrl.dtsi:1083 */
		iomuxc1_gpio_io21_gpio_io_gpio2_io21: IOMUXC1_GPIO_IO21_GPIO_IO_GPIO2_IO21 {
			pinmux = < 0x443c0064 0x0 0x0 0x0 0x443c0214 >; /* in modules/hal/nxp/dts/nxp/nxp_imx/mimx9131cvvxj-pinctrl.dtsi:1084 */
			phandle = < 0x2f >;                             /* in zephyr/dts/arm64/nxp/nxp_mimx9131.dtsi:390 */
		};

		/* node '/iomuxc@443c0000/IOMUXC1_GPIO_IO22_GPIO_IO_GPIO2_IO22' defined in modules/hal/nxp/dts/nxp/nxp_imx/mimx9131cvvxj-pinctrl.dtsi:1110 */
		iomuxc1_gpio_io22_gpio_io_gpio2_io22: IOMUXC1_GPIO_IO22_GPIO_IO_GPIO2_IO22 {
			pinmux = < 0x443c0068 0x0 0x0 0x0 0x443c0218 >; /* in modules/hal/nxp/dts/nxp/nxp_imx/mimx9131cvvxj-pinctrl.dtsi:1111 */
			phandle = < 0x30 >;                             /* in zephyr/dts/arm64/nxp/nxp_mimx9131.dtsi:390 */
		};

		/* node '/iomuxc@443c0000/IOMUXC1_GPIO_IO23_GPIO_IO_GPIO2_IO23' defined in modules/hal/nxp/dts/nxp/nxp_imx/mimx9131cvvxj-pinctrl.dtsi:1134 */
		iomuxc1_gpio_io23_gpio_io_gpio2_io23: IOMUXC1_GPIO_IO23_GPIO_IO_GPIO2_IO23 {
			pinmux = < 0x443c006c 0x0 0x0 0x0 0x443c021c >; /* in modules/hal/nxp/dts/nxp/nxp_imx/mimx9131cvvxj-pinctrl.dtsi:1135 */
			phandle = < 0x31 >;                             /* in zephyr/dts/arm64/nxp/nxp_mimx9131.dtsi:390 */
		};

		/* node '/iomuxc@443c0000/IOMUXC1_GPIO_IO24_GPIO_IO_GPIO2_IO24' defined in modules/hal/nxp/dts/nxp/nxp_imx/mimx9131cvvxj-pinctrl.dtsi:1155 */
		iomuxc1_gpio_io24_gpio_io_gpio2_io24: IOMUXC1_GPIO_IO24_GPIO_IO_GPIO2_IO24 {
			pinmux = < 0x443c0070 0x0 0x0 0x0 0x443c0220 >; /* in modules/hal/nxp/dts/nxp/nxp_imx/mimx9131cvvxj-pinctrl.dtsi:1156 */
			phandle = < 0x32 >;                             /* in zephyr/dts/arm64/nxp/nxp_mimx9131.dtsi:390 */
		};

		/* node '/iomuxc@443c0000/IOMUXC1_GPIO_IO25_GPIO_IO_GPIO2_IO25' defined in modules/hal/nxp/dts/nxp/nxp_imx/mimx9131cvvxj-pinctrl.dtsi:1179 */
		iomuxc1_gpio_io25_gpio_io_gpio2_io25: IOMUXC1_GPIO_IO25_GPIO_IO_GPIO2_IO25 {
			pinmux = < 0x443c0074 0x0 0x0 0x0 0x443c0224 >; /* in modules/hal/nxp/dts/nxp/nxp_imx/mimx9131cvvxj-pinctrl.dtsi:1180 */
			phandle = < 0x33 >;                             /* in zephyr/dts/arm64/nxp/nxp_mimx9131.dtsi:390 */
		};

		/* node '/iomuxc@443c0000/IOMUXC1_GPIO_IO26_GPIO_IO_GPIO2_IO26' defined in modules/hal/nxp/dts/nxp/nxp_imx/mimx9131cvvxj-pinctrl.dtsi:1197 */
		iomuxc1_gpio_io26_gpio_io_gpio2_io26: IOMUXC1_GPIO_IO26_GPIO_IO_GPIO2_IO26 {
			pinmux = < 0x443c0078 0x0 0x0 0x0 0x443c0228 >; /* in modules/hal/nxp/dts/nxp/nxp_imx/mimx9131cvvxj-pinctrl.dtsi:1198 */
			phandle = < 0x34 >;                             /* in zephyr/dts/arm64/nxp/nxp_mimx9131.dtsi:390 */
		};

		/* node '/iomuxc@443c0000/IOMUXC1_GPIO_IO27_GPIO_IO_GPIO2_IO27' defined in modules/hal/nxp/dts/nxp/nxp_imx/mimx9131cvvxj-pinctrl.dtsi:1227 */
		iomuxc1_gpio_io27_gpio_io_gpio2_io27: IOMUXC1_GPIO_IO27_GPIO_IO_GPIO2_IO27 {
			pinmux = < 0x443c007c 0x0 0x0 0x0 0x443c022c >; /* in modules/hal/nxp/dts/nxp/nxp_imx/mimx9131cvvxj-pinctrl.dtsi:1228 */
			phandle = < 0x35 >;                             /* in zephyr/dts/arm64/nxp/nxp_mimx9131.dtsi:390 */
		};

		/* node '/iomuxc@443c0000/IOMUXC1_GPIO_IO28_GPIO_IO_GPIO2_IO28' defined in modules/hal/nxp/dts/nxp/nxp_imx/mimx9131cvvxj-pinctrl.dtsi:1251 */
		iomuxc1_gpio_io28_gpio_io_gpio2_io28: IOMUXC1_GPIO_IO28_GPIO_IO_GPIO2_IO28 {
			pinmux = < 0x443c0080 0x0 0x0 0x0 0x443c0230 >; /* in modules/hal/nxp/dts/nxp/nxp_imx/mimx9131cvvxj-pinctrl.dtsi:1252 */
			phandle = < 0x36 >;                             /* in zephyr/dts/arm64/nxp/nxp_mimx9131.dtsi:390 */
		};

		/* node '/iomuxc@443c0000/IOMUXC1_GPIO_IO29_GPIO_IO_GPIO2_IO29' defined in modules/hal/nxp/dts/nxp/nxp_imx/mimx9131cvvxj-pinctrl.dtsi:1263 */
		iomuxc1_gpio_io29_gpio_io_gpio2_io29: IOMUXC1_GPIO_IO29_GPIO_IO_GPIO2_IO29 {
			pinmux = < 0x443c0084 0x0 0x0 0x0 0x443c0234 >; /* in modules/hal/nxp/dts/nxp/nxp_imx/mimx9131cvvxj-pinctrl.dtsi:1264 */
			phandle = < 0x37 >;                             /* in zephyr/dts/arm64/nxp/nxp_mimx9131.dtsi:390 */
		};

		/* node '/iomuxc@443c0000/IOMUXC1_I2C1_SCL_GPIO_IO_GPIO1_IO0' defined in modules/hal/nxp/dts/nxp/nxp_imx/mimx9131cvvxj-pinctrl.dtsi:1269 */
		iomuxc1_i2c1_scl_gpio_io_gpio1_io0: IOMUXC1_I2C1_SCL_GPIO_IO_GPIO1_IO0 {
			pinmux = < 0x443c0170 0x5 0x0 0x0 0x443c0320 >; /* in modules/hal/nxp/dts/nxp/nxp_imx/mimx9131cvvxj-pinctrl.dtsi:1270 */
			phandle = < 0xa >;                              /* in zephyr/dts/arm64/nxp/nxp_mimx9131.dtsi:371 */
		};

		/* node '/iomuxc@443c0000/IOMUXC1_I2C1_SCL_LPI2C_SCL_LPI2C1_SCL' defined in modules/hal/nxp/dts/nxp/nxp_imx/mimx9131cvvxj-pinctrl.dtsi:1275 */
		iomuxc1_i2c1_scl_lpi2c_scl_lpi2c1_scl: IOMUXC1_I2C1_SCL_LPI2C_SCL_LPI2C1_SCL {
			pinmux = < 0x443c0170 0x0 0x443c03e0 0x2 0x443c0320 >; /* in modules/hal/nxp/dts/nxp/nxp_imx/mimx9131cvvxj-pinctrl.dtsi:1276 */
			phandle = < 0x6 >;                                     /* in zephyr/boards/nxp/imx91_evk/imx91_evk-pinctrl.dtsi:32 */
		};

		/* node '/iomuxc@443c0000/IOMUXC1_I2C1_SDA_GPIO_IO_GPIO1_IO1' defined in modules/hal/nxp/dts/nxp/nxp_imx/mimx9131cvvxj-pinctrl.dtsi:1284 */
		iomuxc1_i2c1_sda_gpio_io_gpio1_io1: IOMUXC1_I2C1_SDA_GPIO_IO_GPIO1_IO1 {
			pinmux = < 0x443c0174 0x5 0x0 0x0 0x443c0324 >; /* in modules/hal/nxp/dts/nxp/nxp_imx/mimx9131cvvxj-pinctrl.dtsi:1285 */
			phandle = < 0xb >;                              /* in zephyr/dts/arm64/nxp/nxp_mimx9131.dtsi:371 */
		};

		/* node '/iomuxc@443c0000/IOMUXC1_I2C1_SDA_LPI2C_SDA_LPI2C1_SDA' defined in modules/hal/nxp/dts/nxp/nxp_imx/mimx9131cvvxj-pinctrl.dtsi:1290 */
		iomuxc1_i2c1_sda_lpi2c_sda_lpi2c1_sda: IOMUXC1_I2C1_SDA_LPI2C_SDA_LPI2C1_SDA {
			pinmux = < 0x443c0174 0x0 0x443c03e4 0x2 0x443c0324 >; /* in modules/hal/nxp/dts/nxp/nxp_imx/mimx9131cvvxj-pinctrl.dtsi:1291 */
			phandle = < 0x7 >;                                     /* in zephyr/boards/nxp/imx91_evk/imx91_evk-pinctrl.dtsi:32 */
		};

		/* node '/iomuxc@443c0000/IOMUXC1_I2C2_SCL_GPIO_IO_GPIO1_IO2' defined in modules/hal/nxp/dts/nxp/nxp_imx/mimx9131cvvxj-pinctrl.dtsi:1299 */
		iomuxc1_i2c2_scl_gpio_io_gpio1_io2: IOMUXC1_I2C2_SCL_GPIO_IO_GPIO1_IO2 {
			pinmux = < 0x443c0178 0x5 0x0 0x0 0x443c0328 >; /* in modules/hal/nxp/dts/nxp/nxp_imx/mimx9131cvvxj-pinctrl.dtsi:1300 */
			phandle = < 0xc >;                              /* in zephyr/dts/arm64/nxp/nxp_mimx9131.dtsi:371 */
		};

		/* node '/iomuxc@443c0000/IOMUXC1_I2C2_SCL_LPI2C_SCL_LPI2C2_SCL' defined in modules/hal/nxp/dts/nxp/nxp_imx/mimx9131cvvxj-pinctrl.dtsi:1308 */
		iomuxc1_i2c2_scl_lpi2c_scl_lpi2c2_scl: IOMUXC1_I2C2_SCL_LPI2C_SCL_LPI2C2_SCL {
			pinmux = < 0x443c0178 0x0 0x443c03e8 0x1 0x443c0328 >; /* in modules/hal/nxp/dts/nxp/nxp_imx/mimx9131cvvxj-pinctrl.dtsi:1309 */
			phandle = < 0x8 >;                                     /* in zephyr/boards/nxp/imx91_evk/imx91_evk-pinctrl.dtsi:43 */
		};

		/* node '/iomuxc@443c0000/IOMUXC1_I2C2_SDA_GPIO_IO_GPIO1_IO3' defined in modules/hal/nxp/dts/nxp/nxp_imx/mimx9131cvvxj-pinctrl.dtsi:1320 */
		iomuxc1_i2c2_sda_gpio_io_gpio1_io3: IOMUXC1_I2C2_SDA_GPIO_IO_GPIO1_IO3 {
			pinmux = < 0x443c017c 0x5 0x0 0x0 0x443c032c >; /* in modules/hal/nxp/dts/nxp/nxp_imx/mimx9131cvvxj-pinctrl.dtsi:1321 */
			phandle = < 0xd >;                              /* in zephyr/dts/arm64/nxp/nxp_mimx9131.dtsi:371 */
		};

		/* node '/iomuxc@443c0000/IOMUXC1_I2C2_SDA_LPI2C_SDA_LPI2C2_SDA' defined in modules/hal/nxp/dts/nxp/nxp_imx/mimx9131cvvxj-pinctrl.dtsi:1323 */
		iomuxc1_i2c2_sda_lpi2c_sda_lpi2c2_sda: IOMUXC1_I2C2_SDA_LPI2C_SDA_LPI2C2_SDA {
			pinmux = < 0x443c017c 0x0 0x443c03ec 0x1 0x443c032c >; /* in modules/hal/nxp/dts/nxp/nxp_imx/mimx9131cvvxj-pinctrl.dtsi:1324 */
			phandle = < 0x9 >;                                     /* in zephyr/boards/nxp/imx91_evk/imx91_evk-pinctrl.dtsi:43 */
		};

		/* node '/iomuxc@443c0000/IOMUXC1_PDM_BIT_STREAM0_GPIO_IO_GPIO1_IO9' defined in modules/hal/nxp/dts/nxp/nxp_imx/mimx9131cvvxj-pinctrl.dtsi:1338 */
		iomuxc1_pdm_bit_stream0_gpio_io_gpio1_io9: IOMUXC1_PDM_BIT_STREAM0_GPIO_IO_GPIO1_IO9 {
			pinmux = < 0x443c0194 0x5 0x0 0x0 0x443c0344 >; /* in modules/hal/nxp/dts/nxp/nxp_imx/mimx9131cvvxj-pinctrl.dtsi:1339 */
			phandle = < 0x13 >;                             /* in zephyr/dts/arm64/nxp/nxp_mimx9131.dtsi:371 */
		};

		/* node '/iomuxc@443c0000/IOMUXC1_PDM_BIT_STREAM1_GPIO_IO_GPIO1_IO10' defined in modules/hal/nxp/dts/nxp/nxp_imx/mimx9131cvvxj-pinctrl.dtsi:1356 */
		iomuxc1_pdm_bit_stream1_gpio_io_gpio1_io10: IOMUXC1_PDM_BIT_STREAM1_GPIO_IO_GPIO1_IO10 {
			pinmux = < 0x443c0198 0x5 0x0 0x0 0x443c0348 >; /* in modules/hal/nxp/dts/nxp/nxp_imx/mimx9131cvvxj-pinctrl.dtsi:1357 */
			phandle = < 0x14 >;                             /* in zephyr/dts/arm64/nxp/nxp_mimx9131.dtsi:371 */
		};

		/* node '/iomuxc@443c0000/IOMUXC1_PDM_CLK_GPIO_IO_GPIO1_IO8' defined in modules/hal/nxp/dts/nxp/nxp_imx/mimx9131cvvxj-pinctrl.dtsi:1374 */
		iomuxc1_pdm_clk_gpio_io_gpio1_io8: IOMUXC1_PDM_CLK_GPIO_IO_GPIO1_IO8 {
			pinmux = < 0x443c0190 0x5 0x0 0x0 0x443c0340 >; /* in modules/hal/nxp/dts/nxp/nxp_imx/mimx9131cvvxj-pinctrl.dtsi:1375 */
			phandle = < 0x12 >;                             /* in zephyr/dts/arm64/nxp/nxp_mimx9131.dtsi:371 */
		};

		/* node '/iomuxc@443c0000/IOMUXC1_SAI1_RXD0_GPIO_IO_GPIO1_IO14' defined in modules/hal/nxp/dts/nxp/nxp_imx/mimx9131cvvxj-pinctrl.dtsi:1386 */
		iomuxc1_sai1_rxd0_gpio_io_gpio1_io14: IOMUXC1_SAI1_RXD0_GPIO_IO_GPIO1_IO14 {
			pinmux = < 0x443c01a8 0x5 0x0 0x0 0x443c0358 >; /* in modules/hal/nxp/dts/nxp/nxp_imx/mimx9131cvvxj-pinctrl.dtsi:1387 */
			phandle = < 0x18 >;                             /* in zephyr/dts/arm64/nxp/nxp_mimx9131.dtsi:371 */
		};

		/* node '/iomuxc@443c0000/IOMUXC1_SAI1_TXC_GPIO_IO_GPIO1_IO12' defined in modules/hal/nxp/dts/nxp/nxp_imx/mimx9131cvvxj-pinctrl.dtsi:1407 */
		iomuxc1_sai1_txc_gpio_io_gpio1_io12: IOMUXC1_SAI1_TXC_GPIO_IO_GPIO1_IO12 {
			pinmux = < 0x443c01a0 0x5 0x0 0x0 0x443c0350 >; /* in modules/hal/nxp/dts/nxp/nxp_imx/mimx9131cvvxj-pinctrl.dtsi:1408 */
			phandle = < 0x16 >;                             /* in zephyr/dts/arm64/nxp/nxp_mimx9131.dtsi:371 */
		};

		/* node '/iomuxc@443c0000/IOMUXC1_SAI1_TXD0_GPIO_IO_GPIO1_IO13' defined in modules/hal/nxp/dts/nxp/nxp_imx/mimx9131cvvxj-pinctrl.dtsi:1425 */
		iomuxc1_sai1_txd0_gpio_io_gpio1_io13: IOMUXC1_SAI1_TXD0_GPIO_IO_GPIO1_IO13 {
			pinmux = < 0x443c01a4 0x5 0x0 0x0 0x443c0354 >; /* in modules/hal/nxp/dts/nxp/nxp_imx/mimx9131cvvxj-pinctrl.dtsi:1426 */
			phandle = < 0x17 >;                             /* in zephyr/dts/arm64/nxp/nxp_mimx9131.dtsi:371 */
		};

		/* node '/iomuxc@443c0000/IOMUXC1_SAI1_TXFS_GPIO_IO_GPIO1_IO11' defined in modules/hal/nxp/dts/nxp/nxp_imx/mimx9131cvvxj-pinctrl.dtsi:1443 */
		iomuxc1_sai1_txfs_gpio_io_gpio1_io11: IOMUXC1_SAI1_TXFS_GPIO_IO_GPIO1_IO11 {
			pinmux = < 0x443c019c 0x5 0x0 0x0 0x443c034c >; /* in modules/hal/nxp/dts/nxp/nxp_imx/mimx9131cvvxj-pinctrl.dtsi:1444 */
			phandle = < 0x15 >;                             /* in zephyr/dts/arm64/nxp/nxp_mimx9131.dtsi:371 */
		};

		/* node '/iomuxc@443c0000/IOMUXC1_SD1_CLK_GPIO_IO_GPIO3_IO8' defined in modules/hal/nxp/dts/nxp/nxp_imx/mimx9131cvvxj-pinctrl.dtsi:1464 */
		iomuxc1_sd1_clk_gpio_io_gpio3_io8: IOMUXC1_SD1_CLK_GPIO_IO_GPIO3_IO8 {
			pinmux = < 0x443c0108 0x5 0x0 0x0 0x443c02b8 >; /* in modules/hal/nxp/dts/nxp/nxp_imx/mimx9131cvvxj-pinctrl.dtsi:1465 */
			phandle = < 0x40 >;                             /* in zephyr/dts/arm64/nxp/nxp_mimx9131.dtsi:423 */
		};

		/* node '/iomuxc@443c0000/IOMUXC1_SD1_CMD_GPIO_IO_GPIO3_IO9' defined in modules/hal/nxp/dts/nxp/nxp_imx/mimx9131cvvxj-pinctrl.dtsi:1476 */
		iomuxc1_sd1_cmd_gpio_io_gpio3_io9: IOMUXC1_SD1_CMD_GPIO_IO_GPIO3_IO9 {
			pinmux = < 0x443c010c 0x5 0x0 0x0 0x443c02bc >; /* in modules/hal/nxp/dts/nxp/nxp_imx/mimx9131cvvxj-pinctrl.dtsi:1477 */
			phandle = < 0x41 >;                             /* in zephyr/dts/arm64/nxp/nxp_mimx9131.dtsi:423 */
		};

		/* node '/iomuxc@443c0000/IOMUXC1_SD1_DATA0_GPIO_IO_GPIO3_IO10' defined in modules/hal/nxp/dts/nxp/nxp_imx/mimx9131cvvxj-pinctrl.dtsi:1488 */
		iomuxc1_sd1_data0_gpio_io_gpio3_io10: IOMUXC1_SD1_DATA0_GPIO_IO_GPIO3_IO10 {
			pinmux = < 0x443c0110 0x5 0x0 0x0 0x443c02c0 >; /* in modules/hal/nxp/dts/nxp/nxp_imx/mimx9131cvvxj-pinctrl.dtsi:1489 */
			phandle = < 0x42 >;                             /* in zephyr/dts/arm64/nxp/nxp_mimx9131.dtsi:423 */
		};

		/* node '/iomuxc@443c0000/IOMUXC1_SD1_DATA1_GPIO_IO_GPIO3_IO11' defined in modules/hal/nxp/dts/nxp/nxp_imx/mimx9131cvvxj-pinctrl.dtsi:1500 */
		iomuxc1_sd1_data1_gpio_io_gpio3_io11: IOMUXC1_SD1_DATA1_GPIO_IO_GPIO3_IO11 {
			pinmux = < 0x443c0114 0x5 0x0 0x0 0x443c02c4 >; /* in modules/hal/nxp/dts/nxp/nxp_imx/mimx9131cvvxj-pinctrl.dtsi:1501 */
			phandle = < 0x43 >;                             /* in zephyr/dts/arm64/nxp/nxp_mimx9131.dtsi:423 */
		};

		/* node '/iomuxc@443c0000/IOMUXC1_SD1_DATA2_GPIO_IO_GPIO3_IO12' defined in modules/hal/nxp/dts/nxp/nxp_imx/mimx9131cvvxj-pinctrl.dtsi:1512 */
		iomuxc1_sd1_data2_gpio_io_gpio3_io12: IOMUXC1_SD1_DATA2_GPIO_IO_GPIO3_IO12 {
			pinmux = < 0x443c0118 0x5 0x0 0x0 0x443c02c8 >; /* in modules/hal/nxp/dts/nxp/nxp_imx/mimx9131cvvxj-pinctrl.dtsi:1513 */
			phandle = < 0x44 >;                             /* in zephyr/dts/arm64/nxp/nxp_mimx9131.dtsi:423 */
		};

		/* node '/iomuxc@443c0000/IOMUXC1_SD1_DATA3_GPIO_IO_GPIO3_IO13' defined in modules/hal/nxp/dts/nxp/nxp_imx/mimx9131cvvxj-pinctrl.dtsi:1527 */
		iomuxc1_sd1_data3_gpio_io_gpio3_io13: IOMUXC1_SD1_DATA3_GPIO_IO_GPIO3_IO13 {
			pinmux = < 0x443c011c 0x5 0x0 0x0 0x443c02cc >; /* in modules/hal/nxp/dts/nxp/nxp_imx/mimx9131cvvxj-pinctrl.dtsi:1528 */
			phandle = < 0x45 >;                             /* in zephyr/dts/arm64/nxp/nxp_mimx9131.dtsi:423 */
		};

		/* node '/iomuxc@443c0000/IOMUXC1_SD1_DATA4_GPIO_IO_GPIO3_IO14' defined in modules/hal/nxp/dts/nxp/nxp_imx/mimx9131cvvxj-pinctrl.dtsi:1542 */
		iomuxc1_sd1_data4_gpio_io_gpio3_io14: IOMUXC1_SD1_DATA4_GPIO_IO_GPIO3_IO14 {
			pinmux = < 0x443c0120 0x5 0x0 0x0 0x443c02d0 >; /* in modules/hal/nxp/dts/nxp/nxp_imx/mimx9131cvvxj-pinctrl.dtsi:1543 */
			phandle = < 0x46 >;                             /* in zephyr/dts/arm64/nxp/nxp_mimx9131.dtsi:423 */
		};

		/* node '/iomuxc@443c0000/IOMUXC1_SD1_DATA5_GPIO_IO_GPIO3_IO15' defined in modules/hal/nxp/dts/nxp/nxp_imx/mimx9131cvvxj-pinctrl.dtsi:1557 */
		iomuxc1_sd1_data5_gpio_io_gpio3_io15: IOMUXC1_SD1_DATA5_GPIO_IO_GPIO3_IO15 {
			pinmux = < 0x443c0124 0x5 0x0 0x0 0x443c02d4 >; /* in modules/hal/nxp/dts/nxp/nxp_imx/mimx9131cvvxj-pinctrl.dtsi:1558 */
			phandle = < 0x47 >;                             /* in zephyr/dts/arm64/nxp/nxp_mimx9131.dtsi:423 */
		};

		/* node '/iomuxc@443c0000/IOMUXC1_SD1_DATA6_GPIO_IO_GPIO3_IO16' defined in modules/hal/nxp/dts/nxp/nxp_imx/mimx9131cvvxj-pinctrl.dtsi:1575 */
		iomuxc1_sd1_data6_gpio_io_gpio3_io16: IOMUXC1_SD1_DATA6_GPIO_IO_GPIO3_IO16 {
			pinmux = < 0x443c0128 0x5 0x0 0x0 0x443c02d8 >; /* in modules/hal/nxp/dts/nxp/nxp_imx/mimx9131cvvxj-pinctrl.dtsi:1576 */
			phandle = < 0x48 >;                             /* in zephyr/dts/arm64/nxp/nxp_mimx9131.dtsi:423 */
		};

		/* node '/iomuxc@443c0000/IOMUXC1_SD1_DATA7_GPIO_IO_GPIO3_IO17' defined in modules/hal/nxp/dts/nxp/nxp_imx/mimx9131cvvxj-pinctrl.dtsi:1593 */
		iomuxc1_sd1_data7_gpio_io_gpio3_io17: IOMUXC1_SD1_DATA7_GPIO_IO_GPIO3_IO17 {
			pinmux = < 0x443c012c 0x5 0x0 0x0 0x443c02dc >; /* in modules/hal/nxp/dts/nxp/nxp_imx/mimx9131cvvxj-pinctrl.dtsi:1594 */
			phandle = < 0x49 >;                             /* in zephyr/dts/arm64/nxp/nxp_mimx9131.dtsi:423 */
		};

		/* node '/iomuxc@443c0000/IOMUXC1_SD1_STROBE_GPIO_IO_GPIO3_IO18' defined in modules/hal/nxp/dts/nxp/nxp_imx/mimx9131cvvxj-pinctrl.dtsi:1611 */
		iomuxc1_sd1_strobe_gpio_io_gpio3_io18: IOMUXC1_SD1_STROBE_GPIO_IO_GPIO3_IO18 {
			pinmux = < 0x443c0130 0x5 0x0 0x0 0x443c02e0 >; /* in modules/hal/nxp/dts/nxp/nxp_imx/mimx9131cvvxj-pinctrl.dtsi:1612 */
			phandle = < 0x4a >;                             /* in zephyr/dts/arm64/nxp/nxp_mimx9131.dtsi:423 */
		};

		/* node '/iomuxc@443c0000/IOMUXC1_SD2_CD_B_GPIO_IO_GPIO3_IO0' defined in modules/hal/nxp/dts/nxp/nxp_imx/mimx9131cvvxj-pinctrl.dtsi:1623 */
		iomuxc1_sd2_cd_b_gpio_io_gpio3_io0: IOMUXC1_SD2_CD_B_GPIO_IO_GPIO3_IO0 {
			pinmux = < 0x443c0150 0x5 0x0 0x0 0x443c0300 >; /* in modules/hal/nxp/dts/nxp/nxp_imx/mimx9131cvvxj-pinctrl.dtsi:1624 */
			phandle = < 0x38 >;                             /* in zephyr/dts/arm64/nxp/nxp_mimx9131.dtsi:423 */
		};

		/* node '/iomuxc@443c0000/IOMUXC1_SD2_CLK_GPIO_IO_GPIO3_IO1' defined in modules/hal/nxp/dts/nxp/nxp_imx/mimx9131cvvxj-pinctrl.dtsi:1641 */
		iomuxc1_sd2_clk_gpio_io_gpio3_io1: IOMUXC1_SD2_CLK_GPIO_IO_GPIO3_IO1 {
			pinmux = < 0x443c0154 0x5 0x0 0x0 0x443c0304 >; /* in modules/hal/nxp/dts/nxp/nxp_imx/mimx9131cvvxj-pinctrl.dtsi:1642 */
			phandle = < 0x39 >;                             /* in zephyr/dts/arm64/nxp/nxp_mimx9131.dtsi:423 */
		};

		/* node '/iomuxc@443c0000/IOMUXC1_SD2_CMD_GPIO_IO_GPIO3_IO2' defined in modules/hal/nxp/dts/nxp/nxp_imx/mimx9131cvvxj-pinctrl.dtsi:1659 */
		iomuxc1_sd2_cmd_gpio_io_gpio3_io2: IOMUXC1_SD2_CMD_GPIO_IO_GPIO3_IO2 {
			pinmux = < 0x443c0158 0x5 0x0 0x0 0x443c0308 >; /* in modules/hal/nxp/dts/nxp/nxp_imx/mimx9131cvvxj-pinctrl.dtsi:1660 */
			phandle = < 0x3a >;                             /* in zephyr/dts/arm64/nxp/nxp_mimx9131.dtsi:423 */
		};

		/* node '/iomuxc@443c0000/IOMUXC1_SD2_DATA0_GPIO_IO_GPIO3_IO3' defined in modules/hal/nxp/dts/nxp/nxp_imx/mimx9131cvvxj-pinctrl.dtsi:1680 */
		iomuxc1_sd2_data0_gpio_io_gpio3_io3: IOMUXC1_SD2_DATA0_GPIO_IO_GPIO3_IO3 {
			pinmux = < 0x443c015c 0x5 0x0 0x0 0x443c030c >; /* in modules/hal/nxp/dts/nxp/nxp_imx/mimx9131cvvxj-pinctrl.dtsi:1681 */
			phandle = < 0x3b >;                             /* in zephyr/dts/arm64/nxp/nxp_mimx9131.dtsi:423 */
		};

		/* node '/iomuxc@443c0000/IOMUXC1_SD2_DATA1_GPIO_IO_GPIO3_IO4' defined in modules/hal/nxp/dts/nxp/nxp_imx/mimx9131cvvxj-pinctrl.dtsi:1698 */
		iomuxc1_sd2_data1_gpio_io_gpio3_io4: IOMUXC1_SD2_DATA1_GPIO_IO_GPIO3_IO4 {
			pinmux = < 0x443c0160 0x5 0x0 0x0 0x443c0310 >; /* in modules/hal/nxp/dts/nxp/nxp_imx/mimx9131cvvxj-pinctrl.dtsi:1699 */
			phandle = < 0x3c >;                             /* in zephyr/dts/arm64/nxp/nxp_mimx9131.dtsi:423 */
		};

		/* node '/iomuxc@443c0000/IOMUXC1_SD2_DATA2_GPIO_IO_GPIO3_IO5' defined in modules/hal/nxp/dts/nxp/nxp_imx/mimx9131cvvxj-pinctrl.dtsi:1713 */
		iomuxc1_sd2_data2_gpio_io_gpio3_io5: IOMUXC1_SD2_DATA2_GPIO_IO_GPIO3_IO5 {
			pinmux = < 0x443c0164 0x5 0x0 0x0 0x443c0314 >; /* in modules/hal/nxp/dts/nxp/nxp_imx/mimx9131cvvxj-pinctrl.dtsi:1714 */
			phandle = < 0x3d >;                             /* in zephyr/dts/arm64/nxp/nxp_mimx9131.dtsi:423 */
		};

		/* node '/iomuxc@443c0000/IOMUXC1_SD2_DATA3_GPIO_IO_GPIO3_IO6' defined in modules/hal/nxp/dts/nxp/nxp_imx/mimx9131cvvxj-pinctrl.dtsi:1728 */
		iomuxc1_sd2_data3_gpio_io_gpio3_io6: IOMUXC1_SD2_DATA3_GPIO_IO_GPIO3_IO6 {
			pinmux = < 0x443c0168 0x5 0x0 0x0 0x443c0318 >; /* in modules/hal/nxp/dts/nxp/nxp_imx/mimx9131cvvxj-pinctrl.dtsi:1729 */
			phandle = < 0x3e >;                             /* in zephyr/dts/arm64/nxp/nxp_mimx9131.dtsi:423 */
		};

		/* node '/iomuxc@443c0000/IOMUXC1_SD2_RESET_B_GPIO_IO_GPIO3_IO7' defined in modules/hal/nxp/dts/nxp/nxp_imx/mimx9131cvvxj-pinctrl.dtsi:1749 */
		iomuxc1_sd2_reset_b_gpio_io_gpio3_io7: IOMUXC1_SD2_RESET_B_GPIO_IO_GPIO3_IO7 {
			pinmux = < 0x443c016c 0x5 0x0 0x0 0x443c031c >; /* in modules/hal/nxp/dts/nxp/nxp_imx/mimx9131cvvxj-pinctrl.dtsi:1750 */
			phandle = < 0x3f >;                             /* in zephyr/dts/arm64/nxp/nxp_mimx9131.dtsi:423 */
		};

		/* node '/iomuxc@443c0000/IOMUXC1_SD2_VSELECT_GPIO_IO_GPIO3_IO19' defined in modules/hal/nxp/dts/nxp/nxp_imx/mimx9131cvvxj-pinctrl.dtsi:1761 */
		iomuxc1_sd2_vselect_gpio_io_gpio3_io19: IOMUXC1_SD2_VSELECT_GPIO_IO_GPIO3_IO19 {
			pinmux = < 0x443c0134 0x5 0x0 0x0 0x443c02e4 >; /* in modules/hal/nxp/dts/nxp/nxp_imx/mimx9131cvvxj-pinctrl.dtsi:1762 */
			phandle = < 0x4b >;                             /* in zephyr/dts/arm64/nxp/nxp_mimx9131.dtsi:423 */
		};

		/* node '/iomuxc@443c0000/IOMUXC1_SD3_CLK_GPIO_IO_GPIO3_IO20' defined in modules/hal/nxp/dts/nxp/nxp_imx/mimx9131cvvxj-pinctrl.dtsi:1779 */
		iomuxc1_sd3_clk_gpio_io_gpio3_io20: IOMUXC1_SD3_CLK_GPIO_IO_GPIO3_IO20 {
			pinmux = < 0x443c0138 0x5 0x0 0x0 0x443c02e8 >; /* in modules/hal/nxp/dts/nxp/nxp_imx/mimx9131cvvxj-pinctrl.dtsi:1780 */
			phandle = < 0x4c >;                             /* in zephyr/dts/arm64/nxp/nxp_mimx9131.dtsi:423 */
		};

		/* node '/iomuxc@443c0000/IOMUXC1_SD3_CMD_GPIO_IO_GPIO3_IO21' defined in modules/hal/nxp/dts/nxp/nxp_imx/mimx9131cvvxj-pinctrl.dtsi:1794 */
		iomuxc1_sd3_cmd_gpio_io_gpio3_io21: IOMUXC1_SD3_CMD_GPIO_IO_GPIO3_IO21 {
			pinmux = < 0x443c013c 0x5 0x0 0x0 0x443c02ec >; /* in modules/hal/nxp/dts/nxp/nxp_imx/mimx9131cvvxj-pinctrl.dtsi:1795 */
			phandle = < 0x4d >;                             /* in zephyr/dts/arm64/nxp/nxp_mimx9131.dtsi:423 */
		};

		/* node '/iomuxc@443c0000/IOMUXC1_SD3_DATA0_GPIO_IO_GPIO3_IO22' defined in modules/hal/nxp/dts/nxp/nxp_imx/mimx9131cvvxj-pinctrl.dtsi:1809 */
		iomuxc1_sd3_data0_gpio_io_gpio3_io22: IOMUXC1_SD3_DATA0_GPIO_IO_GPIO3_IO22 {
			pinmux = < 0x443c0140 0x5 0x0 0x0 0x443c02f0 >; /* in modules/hal/nxp/dts/nxp/nxp_imx/mimx9131cvvxj-pinctrl.dtsi:1810 */
			phandle = < 0x4e >;                             /* in zephyr/dts/arm64/nxp/nxp_mimx9131.dtsi:423 */
		};

		/* node '/iomuxc@443c0000/IOMUXC1_SD3_DATA1_GPIO_IO_GPIO3_IO23' defined in modules/hal/nxp/dts/nxp/nxp_imx/mimx9131cvvxj-pinctrl.dtsi:1824 */
		iomuxc1_sd3_data1_gpio_io_gpio3_io23: IOMUXC1_SD3_DATA1_GPIO_IO_GPIO3_IO23 {
			pinmux = < 0x443c0144 0x5 0x0 0x0 0x443c02f4 >; /* in modules/hal/nxp/dts/nxp/nxp_imx/mimx9131cvvxj-pinctrl.dtsi:1825 */
			phandle = < 0x4f >;                             /* in zephyr/dts/arm64/nxp/nxp_mimx9131.dtsi:423 */
		};

		/* node '/iomuxc@443c0000/IOMUXC1_SD3_DATA2_GPIO_IO_GPIO3_IO24' defined in modules/hal/nxp/dts/nxp/nxp_imx/mimx9131cvvxj-pinctrl.dtsi:1839 */
		iomuxc1_sd3_data2_gpio_io_gpio3_io24: IOMUXC1_SD3_DATA2_GPIO_IO_GPIO3_IO24 {
			pinmux = < 0x443c0148 0x5 0x0 0x0 0x443c02f8 >; /* in modules/hal/nxp/dts/nxp/nxp_imx/mimx9131cvvxj-pinctrl.dtsi:1840 */
			phandle = < 0x50 >;                             /* in zephyr/dts/arm64/nxp/nxp_mimx9131.dtsi:423 */
		};

		/* node '/iomuxc@443c0000/IOMUXC1_SD3_DATA3_GPIO_IO_GPIO3_IO25' defined in modules/hal/nxp/dts/nxp/nxp_imx/mimx9131cvvxj-pinctrl.dtsi:1854 */
		iomuxc1_sd3_data3_gpio_io_gpio3_io25: IOMUXC1_SD3_DATA3_GPIO_IO_GPIO3_IO25 {
			pinmux = < 0x443c014c 0x5 0x0 0x0 0x443c02fc >; /* in modules/hal/nxp/dts/nxp/nxp_imx/mimx9131cvvxj-pinctrl.dtsi:1855 */
			phandle = < 0x51 >;                             /* in zephyr/dts/arm64/nxp/nxp_mimx9131.dtsi:423 */
		};

		/* node '/iomuxc@443c0000/IOMUXC1_UART1_RXD_GPIO_IO_GPIO1_IO4' defined in modules/hal/nxp/dts/nxp/nxp_imx/mimx9131cvvxj-pinctrl.dtsi:1866 */
		iomuxc1_uart1_rxd_gpio_io_gpio1_io4: IOMUXC1_UART1_RXD_GPIO_IO_GPIO1_IO4 {
			pinmux = < 0x443c0180 0x5 0x0 0x0 0x443c0330 >; /* in modules/hal/nxp/dts/nxp/nxp_imx/mimx9131cvvxj-pinctrl.dtsi:1867 */
			phandle = < 0xe >;                              /* in zephyr/dts/arm64/nxp/nxp_mimx9131.dtsi:371 */
		};

		/* node '/iomuxc@443c0000/IOMUXC1_UART1_RXD_LPUART_RX_LPUART1_RX' defined in modules/hal/nxp/dts/nxp/nxp_imx/mimx9131cvvxj-pinctrl.dtsi:1872 */
		iomuxc1_uart1_rxd_lpuart_rx_lpuart1_rx: IOMUXC1_UART1_RXD_LPUART_RX_LPUART1_RX {
			pinmux = < 0x443c0180 0x0 0x443c0458 0x1 0x443c0330 >; /* in modules/hal/nxp/dts/nxp/nxp_imx/mimx9131cvvxj-pinctrl.dtsi:1873 */
			phandle = < 0x2 >;                                     /* in zephyr/boards/nxp/imx91_evk/imx91_evk-pinctrl.dtsi:12 */
		};

		/* node '/iomuxc@443c0000/IOMUXC1_UART1_TXD_GPIO_IO_GPIO1_IO5' defined in modules/hal/nxp/dts/nxp/nxp_imx/mimx9131cvvxj-pinctrl.dtsi:1881 */
		iomuxc1_uart1_txd_gpio_io_gpio1_io5: IOMUXC1_UART1_TXD_GPIO_IO_GPIO1_IO5 {
			pinmux = < 0x443c0184 0x5 0x0 0x0 0x443c0334 >; /* in modules/hal/nxp/dts/nxp/nxp_imx/mimx9131cvvxj-pinctrl.dtsi:1882 */
			phandle = < 0xf >;                              /* in zephyr/dts/arm64/nxp/nxp_mimx9131.dtsi:371 */
		};

		/* node '/iomuxc@443c0000/IOMUXC1_UART1_TXD_LPUART_TX_LPUART1_TX' defined in modules/hal/nxp/dts/nxp/nxp_imx/mimx9131cvvxj-pinctrl.dtsi:1887 */
		iomuxc1_uart1_txd_lpuart_tx_lpuart1_tx: IOMUXC1_UART1_TXD_LPUART_TX_LPUART1_TX {
			pinmux = < 0x443c0184 0x0 0x443c045c 0x1 0x443c0334 >; /* in modules/hal/nxp/dts/nxp/nxp_imx/mimx9131cvvxj-pinctrl.dtsi:1888 */
			phandle = < 0x3 >;                                     /* in zephyr/boards/nxp/imx91_evk/imx91_evk-pinctrl.dtsi:12 */
		};

		/* node '/iomuxc@443c0000/IOMUXC1_UART2_RXD_GPIO_IO_GPIO1_IO6' defined in modules/hal/nxp/dts/nxp/nxp_imx/mimx9131cvvxj-pinctrl.dtsi:1893 */
		iomuxc1_uart2_rxd_gpio_io_gpio1_io6: IOMUXC1_UART2_RXD_GPIO_IO_GPIO1_IO6 {
			pinmux = < 0x443c0188 0x5 0x0 0x0 0x443c0338 >; /* in modules/hal/nxp/dts/nxp/nxp_imx/mimx9131cvvxj-pinctrl.dtsi:1894 */
			phandle = < 0x10 >;                             /* in zephyr/dts/arm64/nxp/nxp_mimx9131.dtsi:371 */
		};

		/* node '/iomuxc@443c0000/IOMUXC1_UART2_RXD_LPUART_RX_LPUART2_RX' defined in modules/hal/nxp/dts/nxp/nxp_imx/mimx9131cvvxj-pinctrl.dtsi:1902 */
		iomuxc1_uart2_rxd_lpuart_rx_lpuart2_rx: IOMUXC1_UART2_RXD_LPUART_RX_LPUART2_RX {
			pinmux = < 0x443c0188 0x0 0x443c0464 0x1 0x443c0338 >; /* in modules/hal/nxp/dts/nxp/nxp_imx/mimx9131cvvxj-pinctrl.dtsi:1903 */
			phandle = < 0x4 >;                                     /* in zephyr/boards/nxp/imx91_evk/imx91_evk-pinctrl.dtsi:22 */
		};

		/* node '/iomuxc@443c0000/IOMUXC1_UART2_TXD_GPIO_IO_GPIO1_IO7' defined in modules/hal/nxp/dts/nxp/nxp_imx/mimx9131cvvxj-pinctrl.dtsi:1911 */
		iomuxc1_uart2_txd_gpio_io_gpio1_io7: IOMUXC1_UART2_TXD_GPIO_IO_GPIO1_IO7 {
			pinmux = < 0x443c018c 0x5 0x0 0x0 0x443c033c >; /* in modules/hal/nxp/dts/nxp/nxp_imx/mimx9131cvvxj-pinctrl.dtsi:1912 */
			phandle = < 0x11 >;                             /* in zephyr/dts/arm64/nxp/nxp_mimx9131.dtsi:371 */
		};

		/* node '/iomuxc@443c0000/IOMUXC1_UART2_TXD_LPUART_TX_LPUART2_TX' defined in modules/hal/nxp/dts/nxp/nxp_imx/mimx9131cvvxj-pinctrl.dtsi:1920 */
		iomuxc1_uart2_txd_lpuart_tx_lpuart2_tx: IOMUXC1_UART2_TXD_LPUART_TX_LPUART2_TX {
			pinmux = < 0x443c018c 0x0 0x443c0468 0x1 0x443c033c >; /* in modules/hal/nxp/dts/nxp/nxp_imx/mimx9131cvvxj-pinctrl.dtsi:1921 */
			phandle = < 0x5 >;                                     /* in zephyr/boards/nxp/imx91_evk/imx91_evk-pinctrl.dtsi:22 */
		};

		/* node '/iomuxc@443c0000/IOMUXC1_WDOG_ANY_GPIO_IO_GPIO1_IO15' defined in modules/hal/nxp/dts/nxp/nxp_imx/mimx9131cvvxj-pinctrl.dtsi:1929 */
		iomuxc1_wdog_any_gpio_io_gpio1_io15: IOMUXC1_WDOG_ANY_GPIO_IO_GPIO1_IO15 {
			pinmux = < 0x443c01ac 0x5 0x0 0x0 0x443c035c >; /* in modules/hal/nxp/dts/nxp/nxp_imx/mimx9131cvvxj-pinctrl.dtsi:1930 */
			phandle = < 0x19 >;                             /* in zephyr/dts/arm64/nxp/nxp_mimx9131.dtsi:371 */
		};
	};

	/* node '/ana_pll@44480000' defined in zephyr/dts/arm64/nxp/nxp_mimx9131.dtsi:68 */
	ana_pll: ana_pll@44480000 {
		compatible = "nxp,imx-ana";   /* in zephyr/dts/arm64/nxp/nxp_mimx9131.dtsi:69 */
		reg = < 0x44480000 0x10000 >; /* in zephyr/dts/arm64/nxp/nxp_mimx9131.dtsi:70 */
	};

	/* node '/ccm@44450000' defined in zephyr/dts/arm64/nxp/nxp_mimx9131.dtsi:73 */
	ccm: ccm@44450000 {
		compatible = "nxp,imx-ccm-rev2"; /* in zephyr/dts/arm64/nxp/nxp_mimx9131.dtsi:74 */
		reg = < 0x44450000 0x10000 >;    /* in zephyr/dts/arm64/nxp/nxp_mimx9131.dtsi:75 */
		#clock-cells = < 0x3 >;          /* in zephyr/dts/arm64/nxp/nxp_mimx9131.dtsi:76 */
		phandle = < 0x76 >;              /* in zephyr/dts/arm64/nxp/nxp_mimx9131.dtsi:149 */
	};

	/* node '/edma@42000000' defined in zephyr/dts/arm64/nxp/nxp_mimx9131.dtsi:79 */
	edma4_2: edma@42000000 {
		compatible = "nxp,mcux-edma";       /* in zephyr/dts/arm64/nxp/nxp_mimx9131.dtsi:80 */
		nxp,version = < 0x4 >;              /* in zephyr/dts/arm64/nxp/nxp_mimx9131.dtsi:81 */
		no-error-irq;                       /* in zephyr/dts/arm64/nxp/nxp_mimx9131.dtsi:82 */
		dma-requests = < 0x9f >;            /* in zephyr/dts/arm64/nxp/nxp_mimx9131.dtsi:83 */
		reg = < 0x42000000 0x400000 >;      /* in zephyr/dts/arm64/nxp/nxp_mimx9131.dtsi:84 */
		dma-channels = < 0x4 >;             /* in zephyr/dts/arm64/nxp/nxp_mimx9131.dtsi:85 */
		interrupt-parent = < &gic >;        /* in zephyr/dts/arm64/nxp/nxp_mimx9131.dtsi:86 */
		interrupts = < 0x0 0x80 0x2 0xa0 >,
		             < 0x0 0x80 0x2 0xa0 >,
		             < 0x0 0x81 0x2 0xa0 >,
		             < 0x0 0x81 0x2 0xa0 >; /* in zephyr/dts/arm64/nxp/nxp_mimx9131.dtsi:87 */
		#dma-cells = < 0x2 >;               /* in zephyr/dts/arm64/nxp/nxp_mimx9131.dtsi:91 */
		status = "disabled";                /* in zephyr/dts/arm64/nxp/nxp_mimx9131.dtsi:92 */
		phandle = < 0x7a >;                 /* in zephyr/dts/arm64/nxp/nxp_mimx9131.dtsi:269 */
	};

	/* node '/gpio@47400000' defined in zephyr/dts/arm64/nxp/nxp_mimx9131.dtsi:95 */
	gpio1: gpio@47400000 {
		compatible = "nxp,imx-rgpio";                             /* in zephyr/dts/arm64/nxp/nxp_mimx9131.dtsi:96 */
		reg = < 0x47400000 0x10000 >;                             /* in zephyr/dts/arm64/nxp/nxp_mimx9131.dtsi:97 */
		interrupt-parent = < &gic >;                              /* in zephyr/dts/arm64/nxp/nxp_mimx9131.dtsi:98 */
		interrupts = < 0x0 0xa 0x2 0xa0 >,
		             < 0x0 0xb 0x2 0xa0 >;                        /* in zephyr/dts/arm64/nxp/nxp_mimx9131.dtsi:99 */
		gpio-controller;                                          /* in zephyr/dts/arm64/nxp/nxp_mimx9131.dtsi:101 */
		#gpio-cells = < 0x2 >;                                    /* in zephyr/dts/arm64/nxp/nxp_mimx9131.dtsi:102 */
		ngpios = < 0x10 >;                                        /* in zephyr/dts/arm64/nxp/nxp_mimx9131.dtsi:103 */
		status = "disabled";                                      /* in zephyr/dts/arm64/nxp/nxp_mimx9131.dtsi:104 */
		pinmux = < &iomuxc1_i2c1_scl_gpio_io_gpio1_io0 >,
		         < &iomuxc1_i2c1_sda_gpio_io_gpio1_io1 >,
		         < &iomuxc1_i2c2_scl_gpio_io_gpio1_io2 >,
		         < &iomuxc1_i2c2_sda_gpio_io_gpio1_io3 >,
		         < &iomuxc1_uart1_rxd_gpio_io_gpio1_io4 >,
		         < &iomuxc1_uart1_txd_gpio_io_gpio1_io5 >,
		         < &iomuxc1_uart2_rxd_gpio_io_gpio1_io6 >,
		         < &iomuxc1_uart2_txd_gpio_io_gpio1_io7 >,
		         < &iomuxc1_pdm_clk_gpio_io_gpio1_io8 >,
		         < &iomuxc1_pdm_bit_stream0_gpio_io_gpio1_io9 >,
		         < &iomuxc1_pdm_bit_stream1_gpio_io_gpio1_io10 >,
		         < &iomuxc1_sai1_txfs_gpio_io_gpio1_io11 >,
		         < &iomuxc1_sai1_txc_gpio_io_gpio1_io12 >,
		         < &iomuxc1_sai1_txd0_gpio_io_gpio1_io13 >,
		         < &iomuxc1_sai1_rxd0_gpio_io_gpio1_io14 >,
		         < &iomuxc1_wdog_any_gpio_io_gpio1_io15 >;        /* in zephyr/dts/arm64/nxp/nxp_mimx9131.dtsi:371 */
	};

	/* node '/gpio@43810000' defined in zephyr/dts/arm64/nxp/nxp_mimx9131.dtsi:107 */
	gpio2: gpio@43810000 {
		compatible = "nxp,imx-rgpio";                       /* in zephyr/dts/arm64/nxp/nxp_mimx9131.dtsi:108 */
		reg = < 0x43810000 0x10000 >;                       /* in zephyr/dts/arm64/nxp/nxp_mimx9131.dtsi:109 */
		interrupt-parent = < &gic >;                        /* in zephyr/dts/arm64/nxp/nxp_mimx9131.dtsi:110 */
		interrupts = < 0x0 0x39 0x2 0xa0 >,
		             < 0x0 0x3a 0x2 0xa0 >;                 /* in zephyr/dts/arm64/nxp/nxp_mimx9131.dtsi:111 */
		gpio-controller;                                    /* in zephyr/dts/arm64/nxp/nxp_mimx9131.dtsi:113 */
		#gpio-cells = < 0x2 >;                              /* in zephyr/dts/arm64/nxp/nxp_mimx9131.dtsi:114 */
		ngpios = < 0x1e >;                                  /* in zephyr/dts/arm64/nxp/nxp_mimx9131.dtsi:115 */
		pinmux = < &iomuxc1_gpio_io00_gpio_io_gpio2_io0 >,
		         < &iomuxc1_gpio_io01_gpio_io_gpio2_io1 >,
		         < &iomuxc1_gpio_io02_gpio_io_gpio2_io2 >,
		         < &iomuxc1_gpio_io03_gpio_io_gpio2_io3 >,
		         < &iomuxc1_gpio_io04_gpio_io_gpio2_io4 >,
		         < &iomuxc1_gpio_io05_gpio_io_gpio2_io5 >,
		         < &iomuxc1_gpio_io06_gpio_io_gpio2_io6 >,
		         < &iomuxc1_gpio_io07_gpio_io_gpio2_io7 >,
		         < &iomuxc1_gpio_io08_gpio_io_gpio2_io8 >,
		         < &iomuxc1_gpio_io09_gpio_io_gpio2_io9 >,
		         < &iomuxc1_gpio_io10_gpio_io_gpio2_io10 >,
		         < &iomuxc1_gpio_io11_gpio_io_gpio2_io11 >,
		         < &iomuxc1_gpio_io12_gpio_io_gpio2_io12 >,
		         < &iomuxc1_gpio_io13_gpio_io_gpio2_io13 >,
		         < &iomuxc1_gpio_io14_gpio_io_gpio2_io14 >,
		         < &iomuxc1_gpio_io15_gpio_io_gpio2_io15 >,
		         < &iomuxc1_gpio_io16_gpio_io_gpio2_io16 >,
		         < &iomuxc1_gpio_io17_gpio_io_gpio2_io17 >,
		         < &iomuxc1_gpio_io18_gpio_io_gpio2_io18 >,
		         < &iomuxc1_gpio_io19_gpio_io_gpio2_io19 >,
		         < &iomuxc1_gpio_io20_gpio_io_gpio2_io20 >,
		         < &iomuxc1_gpio_io21_gpio_io_gpio2_io21 >,
		         < &iomuxc1_gpio_io22_gpio_io_gpio2_io22 >,
		         < &iomuxc1_gpio_io23_gpio_io_gpio2_io23 >,
		         < &iomuxc1_gpio_io24_gpio_io_gpio2_io24 >,
		         < &iomuxc1_gpio_io25_gpio_io_gpio2_io25 >,
		         < &iomuxc1_gpio_io26_gpio_io_gpio2_io26 >,
		         < &iomuxc1_gpio_io27_gpio_io_gpio2_io27 >,
		         < &iomuxc1_gpio_io28_gpio_io_gpio2_io28 >,
		         < &iomuxc1_gpio_io29_gpio_io_gpio2_io29 >; /* in zephyr/dts/arm64/nxp/nxp_mimx9131.dtsi:390 */
		status = "okay";                                    /* in zephyr/boards/nxp/imx91_evk/imx91_evk_mimx9131.dts:78 */
		phandle = < 0x7b >;                                 /* in zephyr/boards/nxp/imx91_evk/imx91_evk_mimx9131.dts:39 */
	};

	/* node '/gpio@43820000' defined in zephyr/dts/arm64/nxp/nxp_mimx9131.dtsi:119 */
	gpio3: gpio@43820000 {
		compatible = "nxp,imx-rgpio";                              /* in zephyr/dts/arm64/nxp/nxp_mimx9131.dtsi:120 */
		reg = < 0x43820000 0x10000 >;                              /* in zephyr/dts/arm64/nxp/nxp_mimx9131.dtsi:121 */
		interrupt-parent = < &gic >;                               /* in zephyr/dts/arm64/nxp/nxp_mimx9131.dtsi:122 */
		interrupts = < 0x0 0x3b 0x2 0xa0 >,
		             < 0x0 0x3c 0x2 0xa0 >;                        /* in zephyr/dts/arm64/nxp/nxp_mimx9131.dtsi:123 */
		gpio-controller;                                           /* in zephyr/dts/arm64/nxp/nxp_mimx9131.dtsi:125 */
		#gpio-cells = < 0x2 >;                                     /* in zephyr/dts/arm64/nxp/nxp_mimx9131.dtsi:126 */
		ngpios = < 0x20 >;                                         /* in zephyr/dts/arm64/nxp/nxp_mimx9131.dtsi:127 */
		status = "disabled";                                       /* in zephyr/dts/arm64/nxp/nxp_mimx9131.dtsi:128 */
		pinmux = < &iomuxc1_sd2_cd_b_gpio_io_gpio3_io0 >,
		         < &iomuxc1_sd2_clk_gpio_io_gpio3_io1 >,
		         < &iomuxc1_sd2_cmd_gpio_io_gpio3_io2 >,
		         < &iomuxc1_sd2_data0_gpio_io_gpio3_io3 >,
		         < &iomuxc1_sd2_data1_gpio_io_gpio3_io4 >,
		         < &iomuxc1_sd2_data2_gpio_io_gpio3_io5 >,
		         < &iomuxc1_sd2_data3_gpio_io_gpio3_io6 >,
		         < &iomuxc1_sd2_reset_b_gpio_io_gpio3_io7 >,
		         < &iomuxc1_sd1_clk_gpio_io_gpio3_io8 >,
		         < &iomuxc1_sd1_cmd_gpio_io_gpio3_io9 >,
		         < &iomuxc1_sd1_data0_gpio_io_gpio3_io10 >,
		         < &iomuxc1_sd1_data1_gpio_io_gpio3_io11 >,
		         < &iomuxc1_sd1_data2_gpio_io_gpio3_io12 >,
		         < &iomuxc1_sd1_data3_gpio_io_gpio3_io13 >,
		         < &iomuxc1_sd1_data4_gpio_io_gpio3_io14 >,
		         < &iomuxc1_sd1_data5_gpio_io_gpio3_io15 >,
		         < &iomuxc1_sd1_data6_gpio_io_gpio3_io16 >,
		         < &iomuxc1_sd1_data7_gpio_io_gpio3_io17 >,
		         < &iomuxc1_sd1_strobe_gpio_io_gpio3_io18 >,
		         < &iomuxc1_sd2_vselect_gpio_io_gpio3_io19 >,
		         < &iomuxc1_sd3_clk_gpio_io_gpio3_io20 >,
		         < &iomuxc1_sd3_cmd_gpio_io_gpio3_io21 >,
		         < &iomuxc1_sd3_data0_gpio_io_gpio3_io22 >,
		         < &iomuxc1_sd3_data1_gpio_io_gpio3_io23 >,
		         < &iomuxc1_sd3_data2_gpio_io_gpio3_io24 >,
		         < &iomuxc1_sd3_data3_gpio_io_gpio3_io25 >,
		         < &iomuxc1_ccm_clko1_gpio_io_gpio3_io26 >,
		         < &iomuxc1_ccm_clko2_gpio_io_gpio3_io27 >,
		         < &iomuxc1_dap_tdi_gpio_io_gpio3_io28 >,
		         < &iomuxc1_dap_tms_swdio_gpio_io_gpio3_io29 >,
		         < &iomuxc1_dap_tclk_swclk_gpio_io_gpio3_io30 >,
		         < &iomuxc1_dap_tdo_traceswo_gpio_io_gpio3_io31 >; /* in zephyr/dts/arm64/nxp/nxp_mimx9131.dtsi:423 */
	};

	/* node '/gpio@43830000' defined in zephyr/dts/arm64/nxp/nxp_mimx9131.dtsi:131 */
	gpio4: gpio@43830000 {
		compatible = "nxp,imx-rgpio";                          /* in zephyr/dts/arm64/nxp/nxp_mimx9131.dtsi:132 */
		reg = < 0x43830000 0x10000 >;                          /* in zephyr/dts/arm64/nxp/nxp_mimx9131.dtsi:133 */
		interrupt-parent = < &gic >;                           /* in zephyr/dts/arm64/nxp/nxp_mimx9131.dtsi:134 */
		interrupts = < 0x0 0xbd 0x2 0xa0 >,
		             < 0x0 0xbe 0x2 0xa0 >;                    /* in zephyr/dts/arm64/nxp/nxp_mimx9131.dtsi:135 */
		gpio-controller;                                       /* in zephyr/dts/arm64/nxp/nxp_mimx9131.dtsi:137 */
		#gpio-cells = < 0x2 >;                                 /* in zephyr/dts/arm64/nxp/nxp_mimx9131.dtsi:138 */
		ngpios = < 0x1e >;                                     /* in zephyr/dts/arm64/nxp/nxp_mimx9131.dtsi:139 */
		status = "disabled";                                   /* in zephyr/dts/arm64/nxp/nxp_mimx9131.dtsi:140 */
		pinmux = < &iomuxc1_enet1_mdc_gpio_io_gpio4_io0 >,
		         < &iomuxc1_enet1_mdio_gpio_io_gpio4_io1 >,
		         < &iomuxc1_enet1_td3_gpio_io_gpio4_io2 >,
		         < &iomuxc1_enet1_td2_gpio_io_gpio4_io3 >,
		         < &iomuxc1_enet1_td1_gpio_io_gpio4_io4 >,
		         < &iomuxc1_enet1_td0_gpio_io_gpio4_io5 >,
		         < &iomuxc1_enet1_tx_ctl_gpio_io_gpio4_io6 >,
		         < &iomuxc1_enet1_txc_gpio_io_gpio4_io7 >,
		         < &iomuxc1_enet1_rx_ctl_gpio_io_gpio4_io8 >,
		         < &iomuxc1_enet1_rxc_gpio_io_gpio4_io9 >,
		         < &iomuxc1_enet1_rd0_gpio_io_gpio4_io10 >,
		         < &iomuxc1_enet1_rd1_gpio_io_gpio4_io11 >,
		         < &iomuxc1_enet1_rd2_gpio_io_gpio4_io12 >,
		         < &iomuxc1_enet1_rd3_gpio_io_gpio4_io13 >,
		         < &iomuxc1_enet2_mdc_gpio_io_gpio4_io14 >,
		         < &iomuxc1_enet2_mdio_gpio_io_gpio4_io15 >,
		         < &iomuxc1_enet2_td3_gpio_io_gpio4_io16 >,
		         < &iomuxc1_enet2_td2_gpio_io_gpio4_io17 >,
		         < &iomuxc1_enet2_td1_gpio_io_gpio4_io18 >,
		         < &iomuxc1_enet2_td0_gpio_io_gpio4_io19 >,
		         < &iomuxc1_enet2_tx_ctl_gpio_io_gpio4_io20 >,
		         < &iomuxc1_enet2_txc_gpio_io_gpio4_io21 >,
		         < &iomuxc1_enet2_rx_ctl_gpio_io_gpio4_io22 >,
		         < &iomuxc1_enet2_rxc_gpio_io_gpio4_io23 >,
		         < &iomuxc1_enet2_rd0_gpio_io_gpio4_io24 >,
		         < &iomuxc1_enet2_rd1_gpio_io_gpio4_io25 >,
		         < &iomuxc1_enet2_rd2_gpio_io_gpio4_io26 >,
		         < &iomuxc1_enet2_rd3_gpio_io_gpio4_io27 >,
		         < &iomuxc1_ccm_clko3_gpio_io_gpio4_io28 >,
		         < &iomuxc1_ccm_clko4_gpio_io_gpio4_io29 >;    /* in zephyr/dts/arm64/nxp/nxp_mimx9131.dtsi:458 */
	};

	/* node '/serial@44380000' defined in zephyr/dts/arm64/nxp/nxp_mimx9131.dtsi:143 */
	lpuart1: serial@44380000 {
		compatible = "nxp,imx-lpuart",
		             "nxp,lpuart";          /* in zephyr/dts/arm64/nxp/nxp_mimx9131.dtsi:144 */
		reg = < 0x44380000 0x10000 >;       /* in zephyr/dts/arm64/nxp/nxp_mimx9131.dtsi:145 */
		interrupts = < 0x0 0x13 0x2 0xa0 >; /* in zephyr/dts/arm64/nxp/nxp_mimx9131.dtsi:146 */
		interrupt-names = "irq_0";          /* in zephyr/dts/arm64/nxp/nxp_mimx9131.dtsi:147 */
		interrupt-parent = < &gic >;        /* in zephyr/dts/arm64/nxp/nxp_mimx9131.dtsi:148 */
		clocks = < &ccm 0x300 0x6c 0x18 >;  /* in zephyr/dts/arm64/nxp/nxp_mimx9131.dtsi:149 */
		status = "okay";                    /* in zephyr/boards/nxp/imx91_evk/imx91_evk_mimx9131.dts:71 */
		current-speed = < 0x1c200 >;        /* in zephyr/boards/nxp/imx91_evk/imx91_evk_mimx9131.dts:72 */
		pinctrl-0 = < &uart1_default >;     /* in zephyr/boards/nxp/imx91_evk/imx91_evk_mimx9131.dts:73 */
		pinctrl-names = "default";          /* in zephyr/boards/nxp/imx91_evk/imx91_evk_mimx9131.dts:74 */
	};

	/* node '/serial@44390000' defined in zephyr/dts/arm64/nxp/nxp_mimx9131.dtsi:153 */
	lpuart2: serial@44390000 {
		compatible = "nxp,imx-lpuart",
		             "nxp,lpuart";          /* in zephyr/dts/arm64/nxp/nxp_mimx9131.dtsi:154 */
		reg = < 0x44390000 0x10000 >;       /* in zephyr/dts/arm64/nxp/nxp_mimx9131.dtsi:155 */
		interrupts = < 0x0 0x14 0x2 0xa0 >; /* in zephyr/dts/arm64/nxp/nxp_mimx9131.dtsi:156 */
		interrupt-names = "irq_0";          /* in zephyr/dts/arm64/nxp/nxp_mimx9131.dtsi:157 */
		interrupt-parent = < &gic >;        /* in zephyr/dts/arm64/nxp/nxp_mimx9131.dtsi:158 */
		clocks = < &ccm 0x301 0x6c 0x18 >;  /* in zephyr/dts/arm64/nxp/nxp_mimx9131.dtsi:159 */
		status = "disabled";                /* in zephyr/dts/arm64/nxp/nxp_mimx9131.dtsi:160 */
	};

	/* node '/i2c@44340000' defined in zephyr/dts/arm64/nxp/nxp_mimx9131.dtsi:163 */
	lpi2c1: i2c@44340000 {
		compatible = "nxp,lpi2c";          /* in zephyr/dts/arm64/nxp/nxp_mimx9131.dtsi:164 */
		#address-cells = < 0x1 >;          /* in zephyr/dts/arm64/nxp/nxp_mimx9131.dtsi:166 */
		#size-cells = < 0x0 >;             /* in zephyr/dts/arm64/nxp/nxp_mimx9131.dtsi:167 */
		reg = < 0x44340000 0x4000 >;       /* in zephyr/dts/arm64/nxp/nxp_mimx9131.dtsi:168 */
		interrupts = < 0x0 0xd 0x2 0xa0 >; /* in zephyr/dts/arm64/nxp/nxp_mimx9131.dtsi:169 */
		interrupt-parent = < &gic >;       /* in zephyr/dts/arm64/nxp/nxp_mimx9131.dtsi:170 */
		clocks = < &ccm 0x400 0x70 0x6 >;  /* in zephyr/dts/arm64/nxp/nxp_mimx9131.dtsi:171 */
		clock-frequency = < 0x61a80 >;     /* in zephyr/boards/nxp/imx91_evk/imx91_evk_mimx9131.dts:82 */
		pinctrl-0 = < &i2c1_default >;     /* in zephyr/boards/nxp/imx91_evk/imx91_evk_mimx9131.dts:83 */
		pinctrl-names = "default";         /* in zephyr/boards/nxp/imx91_evk/imx91_evk_mimx9131.dts:84 */
		status = "okay";                   /* in zephyr/boards/nxp/imx91_evk/imx91_evk_mimx9131.dts:85 */
	};

	/* node '/i2c@44350000' defined in zephyr/dts/arm64/nxp/nxp_mimx9131.dtsi:175 */
	lpi2c2: i2c@44350000 {
		compatible = "nxp,lpi2c";          /* in zephyr/dts/arm64/nxp/nxp_mimx9131.dtsi:176 */
		#address-cells = < 0x1 >;          /* in zephyr/dts/arm64/nxp/nxp_mimx9131.dtsi:178 */
		#size-cells = < 0x0 >;             /* in zephyr/dts/arm64/nxp/nxp_mimx9131.dtsi:179 */
		reg = < 0x44350000 0x4000 >;       /* in zephyr/dts/arm64/nxp/nxp_mimx9131.dtsi:180 */
		interrupts = < 0x0 0xe 0x2 0xa0 >; /* in zephyr/dts/arm64/nxp/nxp_mimx9131.dtsi:181 */
		interrupt-parent = < &gic >;       /* in zephyr/dts/arm64/nxp/nxp_mimx9131.dtsi:182 */
		clocks = < &ccm 0x401 0x70 0x8 >;  /* in zephyr/dts/arm64/nxp/nxp_mimx9131.dtsi:183 */
		clock-frequency = < 0x61a80 >;     /* in zephyr/boards/nxp/imx91_evk/imx91_evk_mimx9131.dts:89 */
		pinctrl-0 = < &i2c2_default >;     /* in zephyr/boards/nxp/imx91_evk/imx91_evk_mimx9131.dts:90 */
		pinctrl-names = "default";         /* in zephyr/boards/nxp/imx91_evk/imx91_evk_mimx9131.dts:91 */
		status = "okay";                   /* in zephyr/boards/nxp/imx91_evk/imx91_evk_mimx9131.dts:92 */
	};

	/* node '/i2c@42530000' defined in zephyr/dts/arm64/nxp/nxp_mimx9131.dtsi:187 */
	lpi2c3: i2c@42530000 {
		compatible = "nxp,lpi2c";           /* in zephyr/dts/arm64/nxp/nxp_mimx9131.dtsi:188 */
		clock-frequency = < 0x186a0 >;      /* in zephyr/dts/arm64/nxp/nxp_mimx9131.dtsi:189 */
		#address-cells = < 0x1 >;           /* in zephyr/dts/arm64/nxp/nxp_mimx9131.dtsi:190 */
		#size-cells = < 0x0 >;              /* in zephyr/dts/arm64/nxp/nxp_mimx9131.dtsi:191 */
		reg = < 0x42530000 0x4000 >;        /* in zephyr/dts/arm64/nxp/nxp_mimx9131.dtsi:192 */
		interrupts = < 0x0 0x3e 0x2 0xa0 >; /* in zephyr/dts/arm64/nxp/nxp_mimx9131.dtsi:193 */
		interrupt-parent = < &gic >;        /* in zephyr/dts/arm64/nxp/nxp_mimx9131.dtsi:194 */
		clocks = < &ccm 0x402 0x70 0xa >;   /* in zephyr/dts/arm64/nxp/nxp_mimx9131.dtsi:195 */
		status = "disabled";                /* in zephyr/dts/arm64/nxp/nxp_mimx9131.dtsi:196 */
	};

	/* node '/i2c@42540000' defined in zephyr/dts/arm64/nxp/nxp_mimx9131.dtsi:199 */
	lpi2c4: i2c@42540000 {
		compatible = "nxp,lpi2c";           /* in zephyr/dts/arm64/nxp/nxp_mimx9131.dtsi:200 */
		clock-frequency = < 0x186a0 >;      /* in zephyr/dts/arm64/nxp/nxp_mimx9131.dtsi:201 */
		#address-cells = < 0x1 >;           /* in zephyr/dts/arm64/nxp/nxp_mimx9131.dtsi:202 */
		#size-cells = < 0x0 >;              /* in zephyr/dts/arm64/nxp/nxp_mimx9131.dtsi:203 */
		reg = < 0x42540000 0x4000 >;        /* in zephyr/dts/arm64/nxp/nxp_mimx9131.dtsi:204 */
		interrupts = < 0x0 0x3f 0x2 0xa0 >; /* in zephyr/dts/arm64/nxp/nxp_mimx9131.dtsi:205 */
		interrupt-parent = < &gic >;        /* in zephyr/dts/arm64/nxp/nxp_mimx9131.dtsi:206 */
		clocks = < &ccm 0x403 0x80 0x18 >;  /* in zephyr/dts/arm64/nxp/nxp_mimx9131.dtsi:207 */
		status = "disabled";                /* in zephyr/dts/arm64/nxp/nxp_mimx9131.dtsi:208 */
	};

	/* node '/i2c@426b0000' defined in zephyr/dts/arm64/nxp/nxp_mimx9131.dtsi:211 */
	lpi2c5: i2c@426b0000 {
		compatible = "nxp,lpi2c";           /* in zephyr/dts/arm64/nxp/nxp_mimx9131.dtsi:212 */
		clock-frequency = < 0x186a0 >;      /* in zephyr/dts/arm64/nxp/nxp_mimx9131.dtsi:213 */
		#address-cells = < 0x1 >;           /* in zephyr/dts/arm64/nxp/nxp_mimx9131.dtsi:214 */
		#size-cells = < 0x0 >;              /* in zephyr/dts/arm64/nxp/nxp_mimx9131.dtsi:215 */
		reg = < 0x426b0000 0x4000 >;        /* in zephyr/dts/arm64/nxp/nxp_mimx9131.dtsi:216 */
		interrupts = < 0x0 0xc3 0x2 0xa0 >; /* in zephyr/dts/arm64/nxp/nxp_mimx9131.dtsi:217 */
		interrupt-parent = < &gic >;        /* in zephyr/dts/arm64/nxp/nxp_mimx9131.dtsi:218 */
		clocks = < &ccm 0x404 0x80 0x18 >;  /* in zephyr/dts/arm64/nxp/nxp_mimx9131.dtsi:219 */
		status = "disabled";                /* in zephyr/dts/arm64/nxp/nxp_mimx9131.dtsi:220 */
	};

	/* node '/i2c@426c0000' defined in zephyr/dts/arm64/nxp/nxp_mimx9131.dtsi:223 */
	lpi2c6: i2c@426c0000 {
		compatible = "nxp,lpi2c";           /* in zephyr/dts/arm64/nxp/nxp_mimx9131.dtsi:224 */
		clock-frequency = < 0x186a0 >;      /* in zephyr/dts/arm64/nxp/nxp_mimx9131.dtsi:225 */
		#address-cells = < 0x1 >;           /* in zephyr/dts/arm64/nxp/nxp_mimx9131.dtsi:226 */
		#size-cells = < 0x0 >;              /* in zephyr/dts/arm64/nxp/nxp_mimx9131.dtsi:227 */
		reg = < 0x426c0000 0x4000 >;        /* in zephyr/dts/arm64/nxp/nxp_mimx9131.dtsi:228 */
		interrupts = < 0x0 0xc4 0x2 0xa0 >; /* in zephyr/dts/arm64/nxp/nxp_mimx9131.dtsi:229 */
		interrupt-parent = < &gic >;        /* in zephyr/dts/arm64/nxp/nxp_mimx9131.dtsi:230 */
		clocks = < &ccm 0x405 0x80 0x18 >;  /* in zephyr/dts/arm64/nxp/nxp_mimx9131.dtsi:231 */
		status = "disabled";                /* in zephyr/dts/arm64/nxp/nxp_mimx9131.dtsi:232 */
	};

	/* node '/i2c@426d0000' defined in zephyr/dts/arm64/nxp/nxp_mimx9131.dtsi:235 */
	lpi2c7: i2c@426d0000 {
		compatible = "nxp,lpi2c";           /* in zephyr/dts/arm64/nxp/nxp_mimx9131.dtsi:236 */
		clock-frequency = < 0x186a0 >;      /* in zephyr/dts/arm64/nxp/nxp_mimx9131.dtsi:237 */
		#address-cells = < 0x1 >;           /* in zephyr/dts/arm64/nxp/nxp_mimx9131.dtsi:238 */
		#size-cells = < 0x0 >;              /* in zephyr/dts/arm64/nxp/nxp_mimx9131.dtsi:239 */
		reg = < 0x426d0000 0x4000 >;        /* in zephyr/dts/arm64/nxp/nxp_mimx9131.dtsi:240 */
		interrupts = < 0x0 0xc5 0x2 0xa0 >; /* in zephyr/dts/arm64/nxp/nxp_mimx9131.dtsi:241 */
		interrupt-parent = < &gic >;        /* in zephyr/dts/arm64/nxp/nxp_mimx9131.dtsi:242 */
		clocks = < &ccm 0x406 0x80 0x18 >;  /* in zephyr/dts/arm64/nxp/nxp_mimx9131.dtsi:243 */
		status = "disabled";                /* in zephyr/dts/arm64/nxp/nxp_mimx9131.dtsi:244 */
	};

	/* node '/i2c@426e0000' defined in zephyr/dts/arm64/nxp/nxp_mimx9131.dtsi:247 */
	lpi2c8: i2c@426e0000 {
		compatible = "nxp,lpi2c";           /* in zephyr/dts/arm64/nxp/nxp_mimx9131.dtsi:248 */
		clock-frequency = < 0x186a0 >;      /* in zephyr/dts/arm64/nxp/nxp_mimx9131.dtsi:249 */
		#address-cells = < 0x1 >;           /* in zephyr/dts/arm64/nxp/nxp_mimx9131.dtsi:250 */
		#size-cells = < 0x0 >;              /* in zephyr/dts/arm64/nxp/nxp_mimx9131.dtsi:251 */
		reg = < 0x426e0000 0x4000 >;        /* in zephyr/dts/arm64/nxp/nxp_mimx9131.dtsi:252 */
		interrupts = < 0x0 0xc6 0x2 0xa0 >; /* in zephyr/dts/arm64/nxp/nxp_mimx9131.dtsi:253 */
		interrupt-parent = < &gic >;        /* in zephyr/dts/arm64/nxp/nxp_mimx9131.dtsi:254 */
		clocks = < &ccm 0x407 0x80 0x18 >;  /* in zephyr/dts/arm64/nxp/nxp_mimx9131.dtsi:255 */
		status = "disabled";                /* in zephyr/dts/arm64/nxp/nxp_mimx9131.dtsi:256 */
	};

	/* node '/sai@42660000' defined in zephyr/dts/arm64/nxp/nxp_mimx9131.dtsi:259 */
	sai3_2: sai@42660000 {
		compatible = "nxp,mcux-i2s";        /* in zephyr/dts/arm64/nxp/nxp_mimx9131.dtsi:260 */
		#address-cells = < 0x1 >;           /* in zephyr/dts/arm64/nxp/nxp_mimx9131.dtsi:261 */
		#size-cells = < 0x0 >;              /* in zephyr/dts/arm64/nxp/nxp_mimx9131.dtsi:262 */
		reg = < 0x42660000 0x10000 >;       /* in zephyr/dts/arm64/nxp/nxp_mimx9131.dtsi:263 */
		clocks = < &ccm 0x1102 0x0 0x0 >;   /* in zephyr/dts/arm64/nxp/nxp_mimx9131.dtsi:264 */
		clock-names = "mclk1";              /* in zephyr/dts/arm64/nxp/nxp_mimx9131.dtsi:265 */
		interrupt-parent = < &gic >;        /* in zephyr/dts/arm64/nxp/nxp_mimx9131.dtsi:266 */
		interrupts = < 0x0 0xab 0x2 0xa0 >; /* in zephyr/dts/arm64/nxp/nxp_mimx9131.dtsi:267 */
		dma-names = "tx",
		            "rx";                   /* in zephyr/dts/arm64/nxp/nxp_mimx9131.dtsi:268 */
		dmas = < &edma4_2 0x2 0x3c >,
		       < &edma4_2 0x3 0x3d >;       /* in zephyr/dts/arm64/nxp/nxp_mimx9131.dtsi:269 */
		nxp,tx-channel = < 0x1 >;           /* in zephyr/dts/arm64/nxp/nxp_mimx9131.dtsi:270 */
		nxp,tx-dma-channel = < 0x2 >;       /* in zephyr/dts/arm64/nxp/nxp_mimx9131.dtsi:271 */
		nxp,rx-dma-channel = < 0x3 >;       /* in zephyr/dts/arm64/nxp/nxp_mimx9131.dtsi:272 */
		nxp,rx-sync-mode;                   /* in zephyr/dts/arm64/nxp/nxp_mimx9131.dtsi:273 */
		status = "disabled";                /* in zephyr/dts/arm64/nxp/nxp_mimx9131.dtsi:274 */
	};

	/* node '/usdhc@42850000' defined in zephyr/dts/arm64/nxp/nxp_mimx9131.dtsi:277 */
	usdhc1: usdhc@42850000 {
		compatible = "nxp,imx-usdhc";       /* in zephyr/dts/arm64/nxp/nxp_mimx9131.dtsi:278 */
		reg = < 0x42850000 0x10000 >;       /* in zephyr/dts/arm64/nxp/nxp_mimx9131.dtsi:279 */
		interrupts = < 0x0 0x56 0x2 0xa0 >; /* in zephyr/dts/arm64/nxp/nxp_mimx9131.dtsi:280 */
		interrupt-parent = < &gic >;        /* in zephyr/dts/arm64/nxp/nxp_mimx9131.dtsi:281 */
		clocks = < &ccm 0x600 0x0 0x0 >;    /* in zephyr/dts/arm64/nxp/nxp_mimx9131.dtsi:282 */
		max-current-330 = < 0x3fc >;        /* in zephyr/dts/arm64/nxp/nxp_mimx9131.dtsi:283 */
		max-current-180 = < 0x3fc >;        /* in zephyr/dts/arm64/nxp/nxp_mimx9131.dtsi:284 */
		max-bus-freq = < 0xc65d400 >;       /* in zephyr/dts/arm64/nxp/nxp_mimx9131.dtsi:285 */
		min-bus-freq = < 0x61a80 >;         /* in zephyr/dts/arm64/nxp/nxp_mimx9131.dtsi:286 */
		status = "disabled";                /* in zephyr/dts/arm64/nxp/nxp_mimx9131.dtsi:287 */
	};

	/* node '/usdhc@42860000' defined in zephyr/dts/arm64/nxp/nxp_mimx9131.dtsi:290 */
	usdhc2: usdhc@42860000 {
		compatible = "nxp,imx-usdhc";       /* in zephyr/dts/arm64/nxp/nxp_mimx9131.dtsi:291 */
		reg = < 0x42860000 0x10000 >;       /* in zephyr/dts/arm64/nxp/nxp_mimx9131.dtsi:292 */
		interrupts = < 0x0 0x57 0x2 0xa0 >; /* in zephyr/dts/arm64/nxp/nxp_mimx9131.dtsi:293 */
		interrupt-parent = < &gic >;        /* in zephyr/dts/arm64/nxp/nxp_mimx9131.dtsi:294 */
		clocks = < &ccm 0x601 0x0 0x0 >;    /* in zephyr/dts/arm64/nxp/nxp_mimx9131.dtsi:295 */
		max-current-330 = < 0x3fc >;        /* in zephyr/dts/arm64/nxp/nxp_mimx9131.dtsi:296 */
		max-current-180 = < 0x3fc >;        /* in zephyr/dts/arm64/nxp/nxp_mimx9131.dtsi:297 */
		max-bus-freq = < 0xc65d400 >;       /* in zephyr/dts/arm64/nxp/nxp_mimx9131.dtsi:298 */
		min-bus-freq = < 0x61a80 >;         /* in zephyr/dts/arm64/nxp/nxp_mimx9131.dtsi:299 */
		status = "disabled";                /* in zephyr/dts/arm64/nxp/nxp_mimx9131.dtsi:300 */
	};

	/* node '/tpm@44310000' defined in zephyr/dts/arm64/nxp/nxp_mimx9131.dtsi:303 */
	tpm1: tpm@44310000 {
		compatible = "nxp,tpm-timer";       /* in zephyr/dts/arm64/nxp/nxp_mimx9131.dtsi:304 */
		reg = < 0x44310000 0x10000 >;       /* in zephyr/dts/arm64/nxp/nxp_mimx9131.dtsi:305 */
		interrupts = < 0x0 0x24 0x2 0xa0 >; /* in zephyr/dts/arm64/nxp/nxp_mimx9131.dtsi:306 */
		interrupt-names = "irq_0";          /* in zephyr/dts/arm64/nxp/nxp_mimx9131.dtsi:307 */
		interrupt-parent = < &gic >;        /* in zephyr/dts/arm64/nxp/nxp_mimx9131.dtsi:308 */
		clocks = < &ccm 0x1600 0x0 0x0 >;   /* in zephyr/dts/arm64/nxp/nxp_mimx9131.dtsi:309 */
		prescaler = < 0x1 >;                /* in zephyr/dts/arm64/nxp/nxp_mimx9131.dtsi:310 */
		status = "disabled";                /* in zephyr/dts/arm64/nxp/nxp_mimx9131.dtsi:311 */
	};

	/* node '/tpm@44320000' defined in zephyr/dts/arm64/nxp/nxp_mimx9131.dtsi:314 */
	tpm2: tpm@44320000 {
		compatible = "nxp,tpm-timer";       /* in zephyr/dts/arm64/nxp/nxp_mimx9131.dtsi:315 */
		reg = < 0x44320000 0x10000 >;       /* in zephyr/dts/arm64/nxp/nxp_mimx9131.dtsi:316 */
		interrupts = < 0x0 0x25 0x2 0xa0 >; /* in zephyr/dts/arm64/nxp/nxp_mimx9131.dtsi:317 */
		interrupt-names = "irq_0";          /* in zephyr/dts/arm64/nxp/nxp_mimx9131.dtsi:318 */
		interrupt-parent = < &gic >;        /* in zephyr/dts/arm64/nxp/nxp_mimx9131.dtsi:319 */
		clocks = < &ccm 0x1601 0x0 0x0 >;   /* in zephyr/dts/arm64/nxp/nxp_mimx9131.dtsi:320 */
		prescaler = < 0x1 >;                /* in zephyr/dts/arm64/nxp/nxp_mimx9131.dtsi:321 */
		status = "okay";                    /* in zephyr/boards/nxp/imx91_evk/imx91_evk_mimx9131.dts:96 */
	};

	/* node '/tpm@424e0000' defined in zephyr/dts/arm64/nxp/nxp_mimx9131.dtsi:325 */
	tpm3: tpm@424e0000 {
		compatible = "nxp,tpm-timer";       /* in zephyr/dts/arm64/nxp/nxp_mimx9131.dtsi:326 */
		reg = < 0x424e0000 0x10000 >;       /* in zephyr/dts/arm64/nxp/nxp_mimx9131.dtsi:327 */
		interrupts = < 0x0 0x4b 0x2 0xa0 >; /* in zephyr/dts/arm64/nxp/nxp_mimx9131.dtsi:328 */
		interrupt-names = "irq_0";          /* in zephyr/dts/arm64/nxp/nxp_mimx9131.dtsi:329 */
		interrupt-parent = < &gic >;        /* in zephyr/dts/arm64/nxp/nxp_mimx9131.dtsi:330 */
		clocks = < &ccm 0x1602 0x0 0x0 >;   /* in zephyr/dts/arm64/nxp/nxp_mimx9131.dtsi:331 */
		prescaler = < 0x1 >;                /* in zephyr/dts/arm64/nxp/nxp_mimx9131.dtsi:332 */
		status = "disabled";                /* in zephyr/dts/arm64/nxp/nxp_mimx9131.dtsi:333 */
	};

	/* node '/tpm@424f0000' defined in zephyr/dts/arm64/nxp/nxp_mimx9131.dtsi:336 */
	tpm4: tpm@424f0000 {
		compatible = "nxp,tpm-timer";       /* in zephyr/dts/arm64/nxp/nxp_mimx9131.dtsi:337 */
		reg = < 0x424f0000 0x10000 >;       /* in zephyr/dts/arm64/nxp/nxp_mimx9131.dtsi:338 */
		interrupts = < 0x0 0x4c 0x2 0xa0 >; /* in zephyr/dts/arm64/nxp/nxp_mimx9131.dtsi:339 */
		interrupt-names = "irq_0";          /* in zephyr/dts/arm64/nxp/nxp_mimx9131.dtsi:340 */
		interrupt-parent = < &gic >;        /* in zephyr/dts/arm64/nxp/nxp_mimx9131.dtsi:341 */
		clocks = < &ccm 0x1603 0x0 0x0 >;   /* in zephyr/dts/arm64/nxp/nxp_mimx9131.dtsi:342 */
		prescaler = < 0x1 >;                /* in zephyr/dts/arm64/nxp/nxp_mimx9131.dtsi:343 */
		status = "disabled";                /* in zephyr/dts/arm64/nxp/nxp_mimx9131.dtsi:344 */
	};

	/* node '/tpm@42500000' defined in zephyr/dts/arm64/nxp/nxp_mimx9131.dtsi:347 */
	tpm5: tpm@42500000 {
		compatible = "nxp,tpm-timer";       /* in zephyr/dts/arm64/nxp/nxp_mimx9131.dtsi:348 */
		reg = < 0x42500000 0x10000 >;       /* in zephyr/dts/arm64/nxp/nxp_mimx9131.dtsi:349 */
		interrupts = < 0x0 0x4d 0x2 0xa0 >; /* in zephyr/dts/arm64/nxp/nxp_mimx9131.dtsi:350 */
		interrupt-names = "irq_0";          /* in zephyr/dts/arm64/nxp/nxp_mimx9131.dtsi:351 */
		interrupt-parent = < &gic >;        /* in zephyr/dts/arm64/nxp/nxp_mimx9131.dtsi:352 */
		clocks = < &ccm 0x1604 0x0 0x0 >;   /* in zephyr/dts/arm64/nxp/nxp_mimx9131.dtsi:353 */
		prescaler = < 0x1 >;                /* in zephyr/dts/arm64/nxp/nxp_mimx9131.dtsi:354 */
		status = "disabled";                /* in zephyr/dts/arm64/nxp/nxp_mimx9131.dtsi:355 */
	};

	/* node '/tpm@42510000' defined in zephyr/dts/arm64/nxp/nxp_mimx9131.dtsi:358 */
	tpm6: tpm@42510000 {
		compatible = "nxp,tpm-timer";       /* in zephyr/dts/arm64/nxp/nxp_mimx9131.dtsi:359 */
		reg = < 0x42510000 0x10000 >;       /* in zephyr/dts/arm64/nxp/nxp_mimx9131.dtsi:360 */
		interrupts = < 0x0 0x4e 0x2 0xa0 >; /* in zephyr/dts/arm64/nxp/nxp_mimx9131.dtsi:361 */
		interrupt-names = "irq_0";          /* in zephyr/dts/arm64/nxp/nxp_mimx9131.dtsi:362 */
		interrupt-parent = < &gic >;        /* in zephyr/dts/arm64/nxp/nxp_mimx9131.dtsi:363 */
		clocks = < &ccm 0x1605 0x0 0x0 >;   /* in zephyr/dts/arm64/nxp/nxp_mimx9131.dtsi:364 */
		prescaler = < 0x1 >;                /* in zephyr/dts/arm64/nxp/nxp_mimx9131.dtsi:365 */
		status = "disabled";                /* in zephyr/dts/arm64/nxp/nxp_mimx9131.dtsi:366 */
	};

	/* node '/memory@80000000' defined in zephyr/boards/nxp/imx91_evk/imx91_evk_mimx9131.dts:24 */
	dram: memory@80000000 {
		reg = < 0x80000000 0x100000 >; /* in zephyr/boards/nxp/imx91_evk/imx91_evk_mimx9131.dts:25 */
	};

	/* node '/leds' defined in zephyr/boards/nxp/imx91_evk/imx91_evk_mimx9131.dts:34 */
	leds {
		compatible = "gpio-leds"; /* in zephyr/boards/nxp/imx91_evk/imx91_evk_mimx9131.dts:35 */

		/* node '/leds/led_r' defined in zephyr/boards/nxp/imx91_evk/imx91_evk_mimx9131.dts:37 */
		led_r: led_r {
			label = "LED_R";            /* in zephyr/boards/nxp/imx91_evk/imx91_evk_mimx9131.dts:38 */
			gpios = < &gpio2 0xd 0x0 >; /* in zephyr/boards/nxp/imx91_evk/imx91_evk_mimx9131.dts:39 */
		};

		/* node '/leds/led_g' defined in zephyr/boards/nxp/imx91_evk/imx91_evk_mimx9131.dts:42 */
		led_g: led_g {
			label = "LED_G";            /* in zephyr/boards/nxp/imx91_evk/imx91_evk_mimx9131.dts:43 */
			gpios = < &gpio2 0x4 0x0 >; /* in zephyr/boards/nxp/imx91_evk/imx91_evk_mimx9131.dts:44 */
		};

		/* node '/leds/led_b' defined in zephyr/boards/nxp/imx91_evk/imx91_evk_mimx9131.dts:47 */
		led_b: led_b {
			label = "LED_B";            /* in zephyr/boards/nxp/imx91_evk/imx91_evk_mimx9131.dts:48 */
			gpios = < &gpio2 0xc 0x0 >; /* in zephyr/boards/nxp/imx91_evk/imx91_evk_mimx9131.dts:49 */
		};
	};

	/* node '/keys' defined in zephyr/boards/nxp/imx91_evk/imx91_evk_mimx9131.dts:53 */
	keys {
		compatible = "gpio-keys"; /* in zephyr/boards/nxp/imx91_evk/imx91_evk_mimx9131.dts:54 */

		/* node '/keys/btn_1' defined in zephyr/boards/nxp/imx91_evk/imx91_evk_mimx9131.dts:56 */
		btn_1: btn_1 {
			label = "BTN1";              /* in zephyr/boards/nxp/imx91_evk/imx91_evk_mimx9131.dts:57 */
			gpios = < &gpio2 0x17 0x1 >; /* in zephyr/boards/nxp/imx91_evk/imx91_evk_mimx9131.dts:58 */
			zephyr,code = < 0xb >;       /* in zephyr/boards/nxp/imx91_evk/imx91_evk_mimx9131.dts:59 */
		};

		/* node '/keys/btn_2' defined in zephyr/boards/nxp/imx91_evk/imx91_evk_mimx9131.dts:62 */
		btn_2: btn_2 {
			label = "BTN2";              /* in zephyr/boards/nxp/imx91_evk/imx91_evk_mimx9131.dts:63 */
			gpios = < &gpio2 0x18 0x1 >; /* in zephyr/boards/nxp/imx91_evk/imx91_evk_mimx9131.dts:64 */
			zephyr,code = < 0x2 >;       /* in zephyr/boards/nxp/imx91_evk/imx91_evk_mimx9131.dts:65 */
		};
	};
};
